// Description: LIN Description file created using Vector's DaVinci Network Designer

// Created: 22 Aug 2023 09:49:13

// Author: t035621

// Version: 0.0

// COM_MATRIX_T2_1.33.0

LIN_description_file;
LIN_protocol_version = "2.1";
LIN_language_version = "2.1";
LIN_speed = 9.6 kbps;

Nodes {
  Master: CCM, 5 ms, 0.5 ms ; // Climate Control Module
  Slaves: CabHeater, CCP, CFAN_L, CFAN_R, CFPM, CTS, DEFS, EACC_24V, WaterHeater ;
}

Signals {
  AtmospherePressureStatus: 8, 255, CCM, WaterHeater, CabHeater ;
  BacklightCmd: 5, 0, CCM, CCP ;
  CabTemperature_Status: 13, 8191, CCM, CabHeater ;
  CTS_Downtime: 12, 4095, CCM, CTS ;
  CTS_DrvDoorOpen: 1, 0, CCM, CTS ;
  CTS_DrvWindowStat: 4, 15, CCM, CTS ;
  CTS_GlazingType: 3, 7, CCM, CTS ;
  CTS_IradianceDrvSide: 6, 63, CCM, CTS ;
  CTS_IradiancePassSide: 6, 63, CCM, CTS ;
  CTS_ParameterSetting: 3, 7, CCM, CTS ;
  CTS_PassDoorOpen: 1, 0, CCM, CTS ;
  CTS_PassWindowStat: 4, 15, CCM, CTS ;
  CTS_RearDrvDoorOpen: 1, 0, CCM, CTS ;
  CTS_RearDrvWindowStat: 4, 15, CCM, CTS ;
  CTS_RearPassDoorOpen: 1, 0, CCM, CTS ;
  CTS_RearPassWindowStat: 4, 15, CCM, CTS ;
  CTS_SoftTopPos: 1, 0, CCM, CTS ;
  CTS_SunBlindPos: 1, 0, CCM, CTS ;
  CTS_SunBlindStat: 4, 15, CCM, CTS ;
  CTS_SunroofPos: 1, 0, CCM, CTS ;
  CTS_SunroofStat: 4, 15, CCM, CTS ;
  DiagInfoCabHeater: 7, 0, CabHeater, CCM ;
  DiagInfoCCP: 7, 0, CCP, CCM ;
  DiagInfoCFanL: 7, 0, CFAN_L, CCM ;
  DiagInfoCFanR: 7, 0, CFAN_R, CCM ;
  DiagInfoCFPM: 7, 0, CFPM, CCM ;
  DiagInfoDEFS: 7, 0, DEFS, CCM ;
  DiagInfoEACC: 7, 0, EACC_24V, CCM ;
  DiagInfoWaterHeater: 7, 0, WaterHeater, CCM ;
  ElecAcCompDrive_cmd: 2, 3, CCM, EACC_24V ;
  ElecAcCompTargetSpeed_cmd: 8, 255, CCM, EACC_24V ;
  ElecCondenserFanActivation_cmd: 2, 3, CCM, CFPM ;
  ElecCondFanOutputTarget_cmd: 8, 255, CCM, CFPM ;
  FanDirectionCFanLCmd: 2, 3, CCM, CFAN_L ;
  FanDirectionCFanRCmd: 2, 3, CCM, CFAN_R ;
  FanSpeedCFanLCmd: 7, 127, CCM, CFAN_L ;
  FanSpeedCFanRCmd: 7, 127, CCM, CFAN_R ;
  FuncIndIlluminationLevel: 3, 1, CCM, CCP ;
  LIN_AC_ButtonStatus: 2, 3, CCP, CCM ;
  LIN_AC_HVACFanIndication_cmd: 4, 15, CCM, CCP ;
  LIN_ACmode_IndicationCmd: 1, 0, CCM, CCP ;
  LIN_AHMaint_stat_BurnerLfTm: 8, 255, CabHeater, CCM ; // 254 Error ; 255 Not Available
  LIN_AHMaint_stat_FanLfTime: 8, 255, CabHeater, CCM ; // 254 Error ; 255 Not Available
  LIN_AHMaint_stat_FuelPmpLfTm: 8, 255, CabHeater, CCM ; // 254 Error ; 255 Not Available
  LIN_AHMaint_stat_GlowPlgLfTm: 8, 255, CabHeater, CCM ; // 254 Error ; 255 Not Available
  LIN_AHMaint_stat_WtrPmpLfTm: 8, 255, CabHeater, CCM ; // 254 Error ; 255 Not Available
  LIN_AHRunTest_Stat1_BurnerTest: 2, 3, CabHeater, CCM ;
  LIN_AHRunTest_Stat1_CO2Level: 8, 255, CabHeater, CCM ; // 254 Error ; 255 Not Available
  LIN_AHRunTest_Stat1_FuelFeeding: 2, 3, CabHeater, CCM ;
  LIN_AHRunTest_Stat1_OpVoltage: 8, 255, CabHeater, CCM ; // 254 Error ; 255 Not Available
  LIN_AHRunTest_Stat1_SetPointTmp: 5, 31, CabHeater, CCM ;
  LIN_AHRunTest_Stat1_TempOutlet: 8, 255, CabHeater, CCM ; // 254 Error ; 255 Not Available
  LIN_AHRunTest_Stat1_WaterSetTmp: 7, 127, CabHeater, CCM ; // 126 Error ; 127 Not available
  LIN_AHRunTest_Stat2_CabTemp: 13, 8191, CabHeater, CCM ; // 8190 Error; 8191 Not Available
  LIN_AHRunTest_Stat2_TempInlet: 10, 1023, CabHeater, CCM ; // 1022 Error ; 1023 Not available
  LIN_AHRunTest_Stat2_WaterTemp: 11, 2047, CabHeater, CCM ; // 2046 Error ; 2047 Not available
  LIN_AirBlowerSpeed_FreeWheelSt: 4, 15, CCP, CCM ;
  LIN_AirFloor_IndicationCmd: 1, 0, CCM, CCP ;
  LIN_AirFlowSelectionDownBtn_st: 2, 3, CCP, CCM ;
  LIN_AirFlowSelectionFrontBtn_s: 2, 3, CCP, CCM ;
  LIN_AirFlowSelectionUpBtn_stat: 2, 3, CCP, CCM ;
  LIN_AirHeater_Stat: 4, 15, CabHeater, CCM ;
  LIN_AirHeaterPowerStatus: 7, 127, CabHeater, CCM ;
  LIN_AirVent_IndicationCmd: 1, 0, CCM, CCP ;
  LIN_AirWindscreen_IndicationCm: 1, 0, CCM, CCP ;
  LIN_Area_9level_Indication_cmd: 4, 15, CCM, CCP ;
  LIN_Auto_ButtonStatus: 2, 3, CCP, CCM ;
  LIN_AutoMode_IndicationCmd: 1, 0, CCM, CCP ;
  LIN_CabInteriorTempVentilatedS: 10, 1023, CCP, CCM ; // 1022 Error; 1023 Not Available
  LIN_CFPM_stat: 2, 3, CFPM, CCM ;
  LIN_CFPMinputCurrent_stat: 8, 255, CFPM, CCM ;
  LIN_CFPMinputVoltage_stat: 9, 511, CFPM, CCM ;
  LIN_ClimateCtrlPanelSleep_cmd: 3, 7, CCM, CCP ;
  LIN_CTS_ItosRaw: 10, 1023, CTS, CCM ;
  LIN_CTS_RefRaw: 10, 1023, CTS, CCM ;
  LIN_CTS_ResponseError: 1, 0, CTS, CCM ;
  LIN_CTS_Solarradiance: 5, 30, CTS, CCM ;
  LIN_CTS_Status: 2, 3, CTS, CCM ;
  LIN_CTS_SunRaw: 10, 1023, CTS, CCM ;
  LIN_CTS_Temperature: 12, 4094, CTS, CCM ;
  LIN_CTS_TempOutofRange: 2, 3, CTS, CCM ;
  LIN_Eco_ButtonStatus: 2, 3, CCP, CCM ;
  LIN_ECOmode_IndicationCmd: 1, 0, CCM, CCP ;
  LIN_ElCondFanOutput_stat: 7, 127, CFPM, CCM ;
  LIN_ElCondFanOutputCurrent_sta: 8, 255, CFPM, CCM ;
  LIN_ElCondFanOutputVolt_stat: 9, 511, CFPM, CCM ;
  LIN_ElecAcCompInputCurrent_sta: 8, 255, EACC_24V, CCM ;
  LIN_ElecAcCompInVoltage_stat: 8, 255, EACC_24V, CCM ;
  LIN_ElecAcCompOperation_stat: 2, 3, EACC_24V, CCM ;
  LIN_ElecAcCompSleepMode_stat: 8, 255, EACC_24V, CCM ;
  LIN_ElecAcCompSpeed_stat: 8, 255, EACC_24V, CCM ;
  LIN_ElecAcCompTemp_stat: 8, 255, EACC_24V, CCM ;
  LIN_ElecAcCompWaitMode_stat: 8, 255, EACC_24V, CCM ;
  LIN_FanCurrentCFanLStat: 8, 255, CFAN_L, CCM ;
  LIN_FanCurrentCFanRStat: 8, 255, CFAN_R, CCM ;
  LIN_FanSpeedCFanLStat: 13, 8191, CFAN_L, CCM ;
  LIN_FanSpeedCFanRStat: 13, 8191, CFAN_R, CCM ;
  LIN_FanVoltageCFanLStat: 9, 511, CFAN_L, CCM ;
  LIN_FanVoltageCFanRStat: 9, 511, CFAN_R, CCM ;
  LIN_FogSensor_CabAirRH: 9, 511, DEFS, CCM ; // 510 Error ; 511 Not available
  LIN_FogSensor_CabAirTemp: 10, 1023, DEFS, CCM ; // 1022 Error ; 1023 Not available
  LIN_FogSensorWindscreenTemp_st: 11, 2047, DEFS, CCM ; // 2046 Error ; 2047 Not available
  LIN_Memo_ButtonStatus: 2, 3, CCP, CCM ;
  LIN_Memo_IndicationCmd: 1, 0, CCM, CCP ;
  LIN_ParkHeaterCooler_ButtonSta: 2, 3, CCP, CCM ;
  LIN_ParkingClimate_IndCmd: 3, 7, CCM, CCP ;
  LIN_Recirc_ButtonStatus: 2, 3, CCP, CCM ;
  LIN_Recirc_IndicationCmd: 1, 0, CCM, CCP ;
  LIN_Temperature_FreeWheelStatu: 4, 15, CCP, CCM ;
  LIN_TemperatureDec_ButtonStatu: 2, 3, CCP, CCM ;
  LIN_TemperatureInc_ButtonStatu: 2, 3, CCP, CCM ;
  LIN_TemperatureRqstIndicatio_c: 5, 31, CCM, CCP ;
  LIN_WaterHeater_Stat: 4, 15, WaterHeater, CCM ;
  LIN_WaterHeaterPowerStatus: 8, 255, WaterHeater, CCM ;
  LIN_WaterHeaterTemperature_Sta: 11, 2047, WaterHeater, CCM ; // 2046 Error ; 2047 Not available
  LIN_WaterPumpStatus: 2, 3, WaterHeater, CCM ;
  LIN_WHMaint_stat_BurnerLfTm: 8, 255, WaterHeater, CCM ; // 254 Error ; 255 Not Available
  LIN_WHMaint_stat_FanLfTime: 8, 255, WaterHeater, CCM ; // 254 Error ; 255 Not Available
  LIN_WHMaint_stat_FuelPmpLfTm: 8, 255, WaterHeater, CCM ; // 254 Error ; 255 Not Available
  LIN_WHMaint_stat_GlowPlgLfTm: 8, 255, WaterHeater, CCM ; // 254 Error ; 255 Not Available
  LIN_WHMaint_stat_WtrPmpLfTm: 8, 255, WaterHeater, CCM ; // 254 Error ; 255 Not Available
  LIN_WHRunTest_Stat1_BurnerTest: 2, 3, WaterHeater, CCM ;
  LIN_WHRunTest_Stat1_CO2Level: 8, 255, WaterHeater, CCM ; // 254 Error ; 255 Not Available
  LIN_WHRunTest_Stat1_FuelFeeding: 2, 3, WaterHeater, CCM ;
  LIN_WHRunTest_Stat1_OpVoltage: 8, 255, WaterHeater, CCM ; // 254 Error ; 255 Not Available
  LIN_WHRunTest_Stat1_SetPointTmp: 5, 31, WaterHeater, CCM ;
  LIN_WHRunTest_Stat1_TempOutlet: 8, 255, WaterHeater, CCM ; // 254 Error ; 255 Not Available
  LIN_WHRunTest_Stat1_WaterSetTmp: 7, 127, WaterHeater, CCM ; // 126 Error ; 127 Not available
  LIN_WHRunTest_Stat2_CabTemp: 13, 8191, WaterHeater, CCM ; // 8190 Error; 8191 Not Available
  LIN_WHRunTest_Stat2_TempInlet: 10, 1023, WaterHeater, CCM ; // 1022 Error ; 1023 Not available
  LIN_WHRunTest_Stat2_WaterTemp: 11, 2047, WaterHeater, CCM ; // 2046 Error ; 2047 Not available
  LIN_WindscreenDefrost_ButtonSt: 2, 3, CCP, CCM ;
  LIN_WindscreenDefrostInd_cmd: 1, 0, CCM, CCP ;
  PH_Activation_cmd: 3, 7, CCM, CabHeater, WaterHeater ;
  PHMasterMode_cmd_DosingPump: 7, 127, CCM, WaterHeater, CabHeater ; // 126 Error ; 127 Not available
  PHMasterMode_cmd_GlowPlug: 7, 127, CCM, CabHeater, WaterHeater ; // 126 Error ; 127 Not available
  PHMasterMode_cmd_HeatingFan: 7, 127, CCM, CabHeater, WaterHeater ; // 126 Error ; 127 Not available
  PHMasterMode_cmd_RunningTime: 8, 0, CCM, CabHeater, WaterHeater ;
  PHMasterMode_cmd_WaterPump: 2, 3, CCM, WaterHeater, CabHeater ;
  PHRunTest_cmd_Burner_cmd: 2, 3, CCM, WaterHeater, CabHeater ;
  PHRunTest_cmd_CO2Adjustment_cmd: 2, 3, CCM, CabHeater, WaterHeater ;
  PHRunTest_cmd_CO2Level: 8, 255, CCM, WaterHeater, CabHeater ; // 254 Error ; 255 Not Available
  PHRunTest_cmd_FuelFeeding_cmd: 2, 3, CCM, WaterHeater, CabHeater ;
  PHRunTest_cmd_FuelFeedTime: 9, 511, CCM, CabHeater, WaterHeater ; // 510 Error ; 511 Not Available
  PHRunTest_cmd_ReadSensor: 4, 15, CCM, WaterHeater, CabHeater ;
  PHRunTest_cmd_ResetCounter: 4, 15, CCM, CabHeater, WaterHeater ;
  PHRunTest_cmd_RstFaultCodes: 2, 3, CCM, CabHeater, WaterHeater ;
  ResponseErrorCabHeater: 1, 0, CabHeater, CCM ;
  ResponseErrorCCP: 1, 0, CCP, CCM ;
  ResponseErrorCFAN_L: 1, 0, CFAN_L, CCM ;
  ResponseErrorCFAN_R: 1, 0, CFAN_R, CCM ;
  ResponseErrorCFPM: 1, 0, CFPM, CCM ;
  ResponseErrorDEFS: 1, 0, DEFS, CCM ;
  ResponseErrorEACC: 1, 0, EACC_24V, CCM ;
  ResponseErrorWaterHeater: 1, 0, WaterHeater, CCM ;
  TempRqst_cmd: 5, 31, CCM, CabHeater ;
  WaterHeaterSetTemp_cmd: 7, 127, CCM, WaterHeater ;
}

Frames {
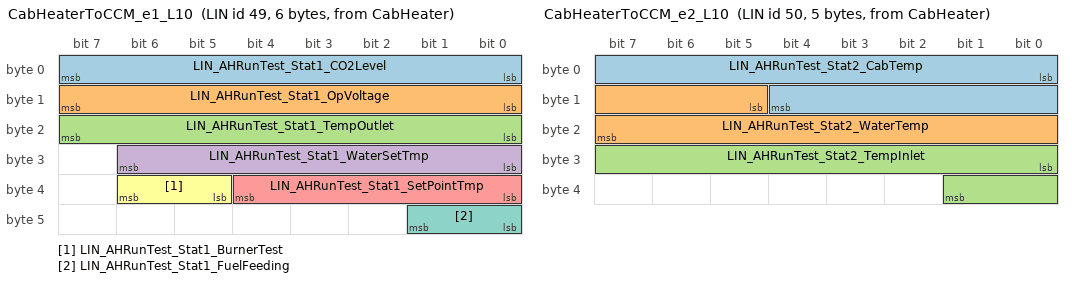
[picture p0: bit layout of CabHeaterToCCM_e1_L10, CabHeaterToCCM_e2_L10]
  CabHeaterToCCM_e1_L10: 49, CabHeater, 6 {
    LIN_AHRunTest_Stat1_CO2Level, 0 ;
    LIN_AHRunTest_Stat1_OpVoltage, 8 ;
    LIN_AHRunTest_Stat1_TempOutlet, 16 ;
    LIN_AHRunTest_Stat1_WaterSetTmp, 24 ;
    LIN_AHRunTest_Stat1_SetPointTmp, 32 ;
    LIN_AHRunTest_Stat1_BurnerTest, 37 ;
    LIN_AHRunTest_Stat1_FuelFeeding, 40 ;
  }
  CabHeaterToCCM_e2_L10: 50, CabHeater, 5 {
    LIN_AHRunTest_Stat2_CabTemp, 0 ;
    LIN_AHRunTest_Stat2_WaterTemp, 13 ;
    LIN_AHRunTest_Stat2_TempInlet, 24 ;
  }
  CabHeaterToCCM_FR2_L10: 46, CabHeater, 2 {
    LIN_AirHeaterPowerStatus, 0 ;
  }
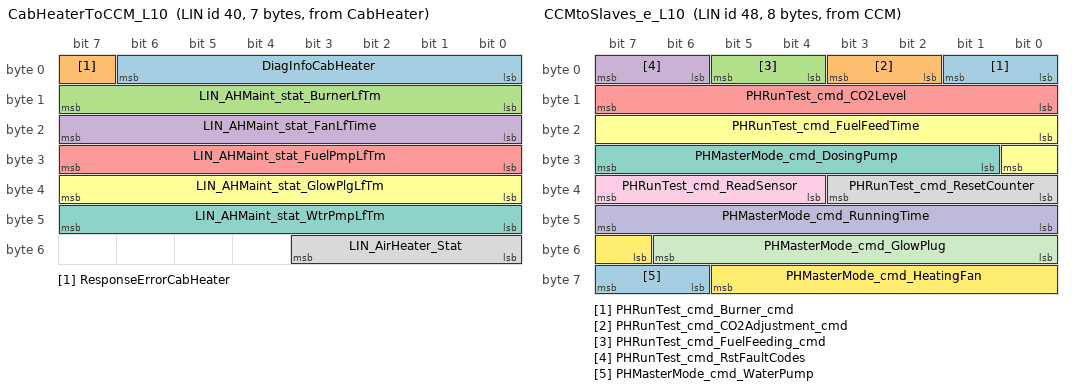
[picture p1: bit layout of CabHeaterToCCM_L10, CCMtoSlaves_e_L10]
  CabHeaterToCCM_L10: 40, CabHeater, 7 {
    DiagInfoCabHeater, 0 ;
    ResponseErrorCabHeater, 7 ;
    LIN_AHMaint_stat_BurnerLfTm, 8 ;
    LIN_AHMaint_stat_FanLfTime, 16 ;
    LIN_AHMaint_stat_FuelPmpLfTm, 24 ;
    LIN_AHMaint_stat_GlowPlgLfTm, 32 ;
    LIN_AHMaint_stat_WtrPmpLfTm, 40 ;
    LIN_AirHeater_Stat, 48 ;
  }
  CCMtoCTS_L10: 54, CCM, 8 {
    CTS_IradianceDrvSide, 0 ;
    CTS_DrvDoorOpen, 6 ;
    CTS_PassDoorOpen, 7 ;
    CTS_IradiancePassSide, 8 ;
    CTS_RearDrvDoorOpen, 14 ;
    CTS_RearPassDoorOpen, 15 ;
    CTS_DrvWindowStat, 16 ;
    CTS_PassWindowStat, 20 ;
    CTS_RearDrvWindowStat, 24 ;
    CTS_RearPassWindowStat, 28 ;
    CTS_SunroofStat, 32 ;
    CTS_SunBlindStat, 36 ;
    CTS_GlazingType, 40 ;
    CTS_ParameterSetting, 43 ;
    CTS_SunroofPos, 46 ;
    CTS_SunBlindPos, 47 ;
    CTS_Downtime, 48 ;
    CTS_SoftTopPos, 60 ;
  }
  CCMtoSlaves_e_L10: 48, CCM, 8 {
    PHRunTest_cmd_Burner_cmd, 0 ;
    PHRunTest_cmd_CO2Adjustment_cmd, 2 ;
    PHRunTest_cmd_FuelFeeding_cmd, 4 ;
    PHRunTest_cmd_RstFaultCodes, 6 ;
    PHRunTest_cmd_CO2Level, 8 ;
    PHRunTest_cmd_FuelFeedTime, 16 ;
    PHMasterMode_cmd_DosingPump, 25 ;
    PHRunTest_cmd_ResetCounter, 32 ;
    PHRunTest_cmd_ReadSensor, 36 ;
    PHMasterMode_cmd_RunningTime, 40 ;
    PHMasterMode_cmd_GlowPlug, 48 ;
    PHMasterMode_cmd_HeatingFan, 55 ;
    PHMasterMode_cmd_WaterPump, 62 ;
  }
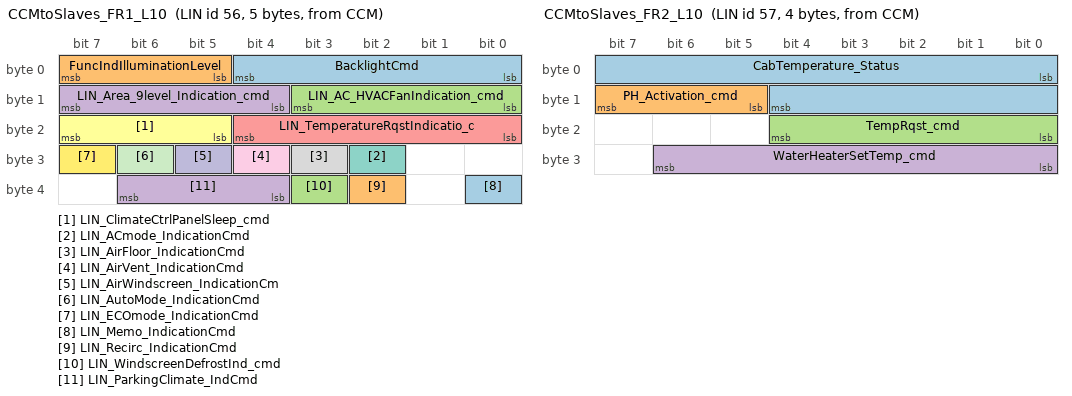
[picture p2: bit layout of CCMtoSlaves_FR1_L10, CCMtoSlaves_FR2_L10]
  CCMtoSlaves_FR1_L10: 56, CCM, 5 {
    BacklightCmd, 0 ;
    FuncIndIlluminationLevel, 5 ;
    LIN_AC_HVACFanIndication_cmd, 8 ;
    LIN_Area_9level_Indication_cmd, 12 ;
    LIN_TemperatureRqstIndicatio_c, 16 ;
    LIN_ClimateCtrlPanelSleep_cmd, 21 ;
    LIN_ACmode_IndicationCmd, 26 ;
    LIN_AirFloor_IndicationCmd, 27 ;
    LIN_AirVent_IndicationCmd, 28 ;
    LIN_AirWindscreen_IndicationCm, 29 ;
    LIN_AutoMode_IndicationCmd, 30 ;
    LIN_ECOmode_IndicationCmd, 31 ;
    LIN_Memo_IndicationCmd, 32 ;
    LIN_Recirc_IndicationCmd, 34 ;
    LIN_WindscreenDefrostInd_cmd, 35 ;
    LIN_ParkingClimate_IndCmd, 36 ;
  }
  CCMtoSlaves_FR2_L10: 57, CCM, 4 {
    CabTemperature_Status, 0 ;
    PH_Activation_cmd, 13 ;
    TempRqst_cmd, 16 ;
    WaterHeaterSetTemp_cmd, 24 ;
  }
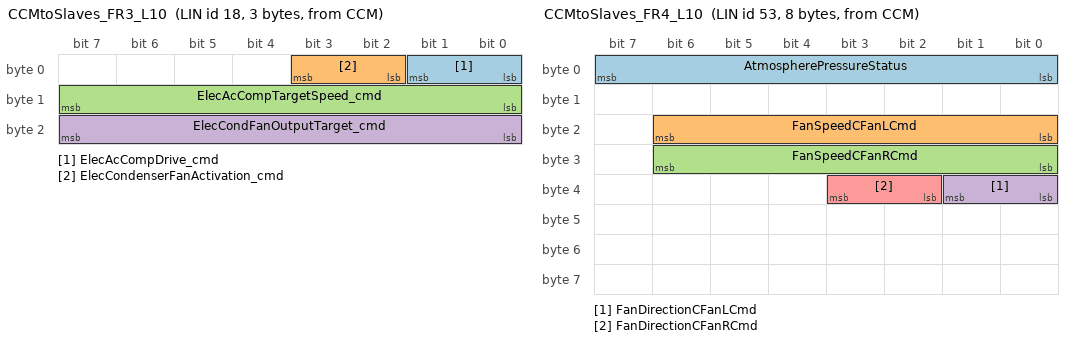
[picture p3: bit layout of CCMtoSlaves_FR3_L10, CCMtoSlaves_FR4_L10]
  CCMtoSlaves_FR3_L10: 18, CCM, 3 {
    ElecAcCompDrive_cmd, 0 ;
    ElecCondenserFanActivation_cmd, 2 ;
    ElecAcCompTargetSpeed_cmd, 8 ;
    ElecCondFanOutputTarget_cmd, 16 ;
  }
  CCMtoSlaves_FR4_L10: 53, CCM, 8 {
    AtmospherePressureStatus, 0 ;
    FanSpeedCFanLCmd, 16 ;
    FanSpeedCFanRCmd, 24 ;
    FanDirectionCFanLCmd, 32 ;
    FanDirectionCFanRCmd, 34 ;
  }
  CCPtoCCM_L10: 26, CCP, 7 {
    DiagInfoCCP, 0 ;
    ResponseErrorCCP, 7 ;
    LIN_AC_ButtonStatus, 8 ;
    LIN_AirBlowerSpeed_FreeWheelSt, 10 ;
    LIN_AirFlowSelectionDownBtn_st, 14 ;
    LIN_AirFlowSelectionFrontBtn_s, 16 ;
    LIN_AirFlowSelectionUpBtn_stat, 18 ;
    LIN_Auto_ButtonStatus, 20 ;
    LIN_Eco_ButtonStatus, 22 ;
    LIN_Memo_ButtonStatus, 24 ;
    LIN_ParkHeaterCooler_ButtonSta, 26 ;
    LIN_Recirc_ButtonStatus, 28 ;
    LIN_TemperatureDec_ButtonStatu, 30 ;
    LIN_Temperature_FreeWheelStatu, 32 ;
    LIN_TemperatureInc_ButtonStatu, 36 ;
    LIN_WindscreenDefrost_ButtonSt, 38 ;
    LIN_CabInteriorTempVentilatedS, 40 ;
  }
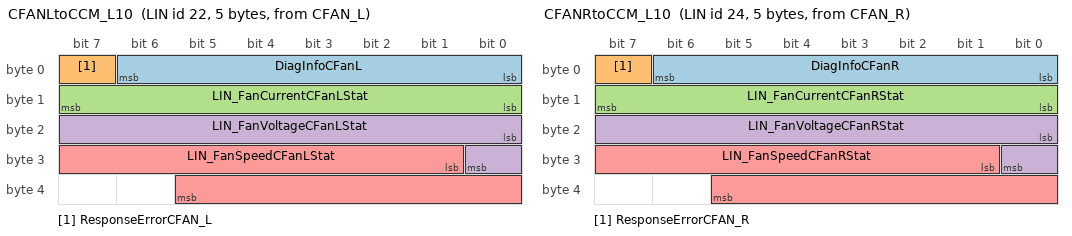
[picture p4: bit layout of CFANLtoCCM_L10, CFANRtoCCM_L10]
  CFANLtoCCM_L10: 22, CFAN_L, 5 {
    DiagInfoCFanL, 0 ;
    ResponseErrorCFAN_L, 7 ;
    LIN_FanCurrentCFanLStat, 8 ;
    LIN_FanVoltageCFanLStat, 16 ;
    LIN_FanSpeedCFanLStat, 25 ;
  }
  CFANRtoCCM_L10: 24, CFAN_R, 5 {
    DiagInfoCFanR, 0 ;
    ResponseErrorCFAN_R, 7 ;
    LIN_FanCurrentCFanRStat, 8 ;
    LIN_FanVoltageCFanRStat, 16 ;
    LIN_FanSpeedCFanRStat, 25 ;
  }
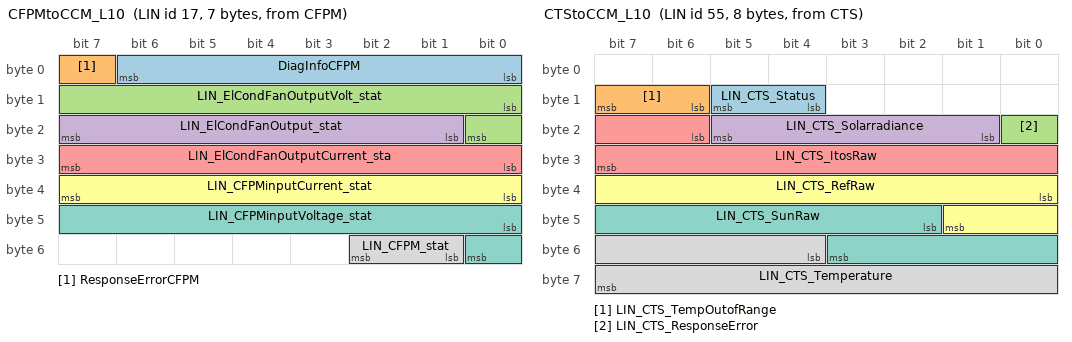
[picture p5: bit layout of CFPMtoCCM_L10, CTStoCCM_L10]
  CFPMtoCCM_L10: 17, CFPM, 7 {
    DiagInfoCFPM, 0 ;
    ResponseErrorCFPM, 7 ;
    LIN_ElCondFanOutputVolt_stat, 8 ;
    LIN_ElCondFanOutput_stat, 17 ;
    LIN_ElCondFanOutputCurrent_sta, 24 ;
    LIN_CFPMinputCurrent_stat, 32 ;
    LIN_CFPMinputVoltage_stat, 40 ;
    LIN_CFPM_stat, 49 ;
  }
  CTStoCCM_L10: 55, CTS, 8 {
    LIN_CTS_Status, 12 ;
    LIN_CTS_TempOutofRange, 14 ;
    LIN_CTS_ResponseError, 16 ;
    LIN_CTS_Solarradiance, 17 ;
    LIN_CTS_ItosRaw, 22 ;
    LIN_CTS_RefRaw, 32 ;
    LIN_CTS_SunRaw, 42 ;
    LIN_CTS_Temperature, 52 ;
  }
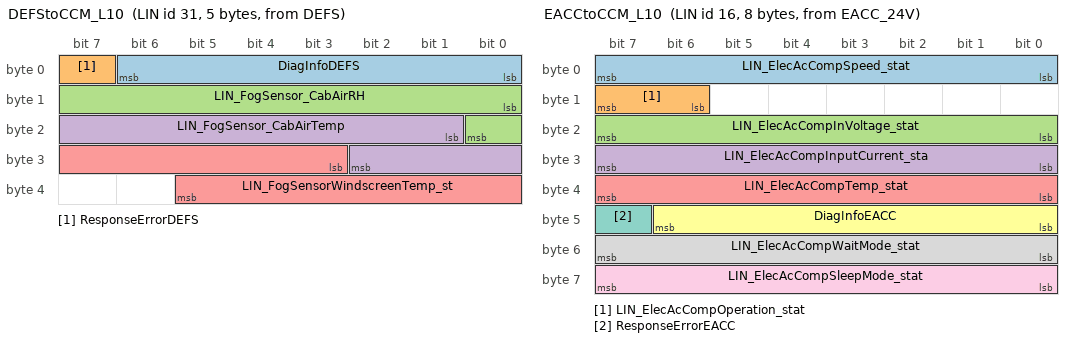
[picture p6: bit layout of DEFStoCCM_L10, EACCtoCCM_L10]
  DEFStoCCM_L10: 31, DEFS, 5 {
    DiagInfoDEFS, 0 ;
    ResponseErrorDEFS, 7 ;
    LIN_FogSensor_CabAirRH, 8 ;
    LIN_FogSensor_CabAirTemp, 17 ;
    LIN_FogSensorWindscreenTemp_st, 27 ;
  }
  EACCtoCCM_L10: 16, EACC_24V, 8 {
    LIN_ElecAcCompSpeed_stat, 0 ;
    LIN_ElecAcCompOperation_stat, 14 ;
    LIN_ElecAcCompInVoltage_stat, 16 ;
    LIN_ElecAcCompInputCurrent_sta, 24 ;
    LIN_ElecAcCompTemp_stat, 32 ;
    DiagInfoEACC, 40 ;
    ResponseErrorEACC, 47 ;
    LIN_ElecAcCompWaitMode_stat, 48 ;
    LIN_ElecAcCompSleepMode_stat, 56 ;
  }
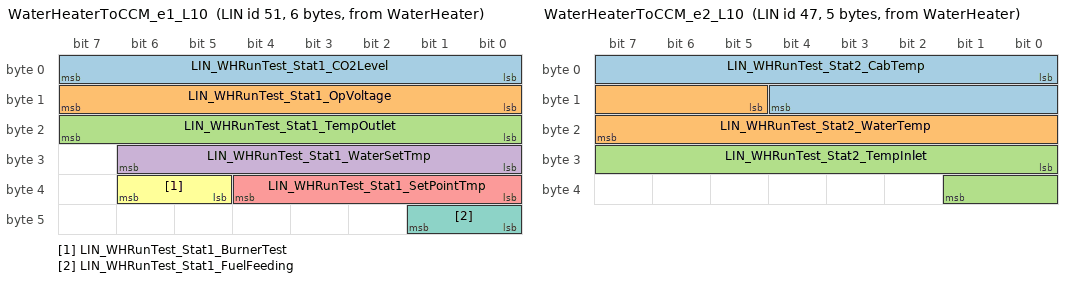
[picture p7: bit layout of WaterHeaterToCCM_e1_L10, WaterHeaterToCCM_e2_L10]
  WaterHeaterToCCM_e1_L10: 51, WaterHeater, 6 {
    LIN_WHRunTest_Stat1_CO2Level, 0 ;
    LIN_WHRunTest_Stat1_OpVoltage, 8 ;
    LIN_WHRunTest_Stat1_TempOutlet, 16 ;
    LIN_WHRunTest_Stat1_WaterSetTmp, 24 ;
    LIN_WHRunTest_Stat1_SetPointTmp, 32 ;
    LIN_WHRunTest_Stat1_BurnerTest, 37 ;
    LIN_WHRunTest_Stat1_FuelFeeding, 40 ;
  }
  WaterHeaterToCCM_e2_L10: 47, WaterHeater, 5 {
    LIN_WHRunTest_Stat2_CabTemp, 0 ;
    LIN_WHRunTest_Stat2_WaterTemp, 13 ;
    LIN_WHRunTest_Stat2_TempInlet, 24 ;
  }
  WaterHeaterToCCM_FR2_L10: 42, WaterHeater, 2 {
    LIN_WaterPumpStatus, 0 ;
    LIN_WaterHeaterPowerStatus, 8 ;
  }
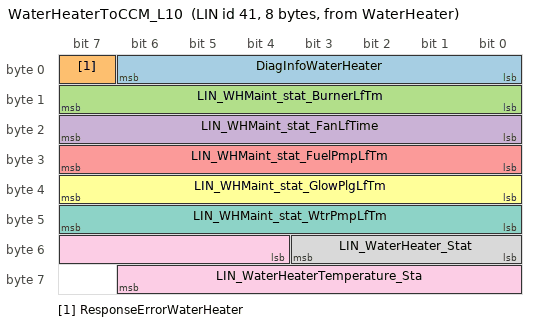
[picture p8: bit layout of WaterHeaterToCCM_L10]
  WaterHeaterToCCM_L10: 41, WaterHeater, 8 {
    DiagInfoWaterHeater, 0 ;
    ResponseErrorWaterHeater, 7 ;
    LIN_WHMaint_stat_BurnerLfTm, 8 ;
    LIN_WHMaint_stat_FanLfTime, 16 ;
    LIN_WHMaint_stat_FuelPmpLfTm, 24 ;
    LIN_WHMaint_stat_GlowPlgLfTm, 32 ;
    LIN_WHMaint_stat_WtrPmpLfTm, 40 ;
    LIN_WaterHeater_Stat, 48 ;
    LIN_WaterHeaterTemperature_Sta, 52 ;
  }
}

Node_attributes {
  CabHeater{
    LIN_protocol = "2.0" ;
    configured_NAD = 0x28 ;
    product_id = 0x5b, 0x0, 0 ;
    response_error = ResponseErrorCabHeater ;
    P2_min = 0 ms ;
    ST_min = 0 ms ;
    configurable_frames {
      CabHeaterToCCM_L10 = 0x28 ;
      CabHeaterToCCM_FR2_L10 = 0x2e ;
      CCMtoSlaves_e_L10 = 0x30 ;
      CabHeaterToCCM_e1_L10 = 0x31 ;
      CabHeaterToCCM_e2_L10 = 0x32 ;
      CCMtoSlaves_FR4_L10 = 0x35 ;
      CCMtoSlaves_FR2_L10 = 0x39 ;
    }
  } // Parking Air Heater Cab
  CCP{
    LIN_protocol = "2.0" ;
    configured_NAD = 0x1a ;
    product_id = 0x5b, 0x0, 0 ;
    response_error = ResponseErrorCCP ;
    P2_min = 0 ms ;
    ST_min = 0 ms ;
    configurable_frames {
      CCPtoCCM_L10 = 0x1a ;
      CCMtoSlaves_FR1_L10 = 0x38 ;
    }
  } // Climate Control Panel
  CFAN_L{
    LIN_protocol = "2.1" ;
    configured_NAD = 0x4d ;
    initial_NAD = 0x4d ;
    product_id = 0x5b, 0x0, 0 ;
    response_error = ResponseErrorCFAN_L ;
    N_As_timeout = 1000 ms ;
    N_Cr_timeout = 1000 ms ;
    configurable_frames {
      CFANLtoCCM_L10 ;
      CCMtoSlaves_FR4_L10 ;
    }
  } // CondenserFan Left
  CFAN_R{
    LIN_protocol = "2.1" ;
    configured_NAD = 0x4e ;
    initial_NAD = 0x4e ;
    product_id = 0x5b, 0x0, 0 ;
    response_error = ResponseErrorCFAN_R ;
    N_As_timeout = 1000 ms ;
    N_Cr_timeout = 1000 ms ;
    configurable_frames {
      CFANRtoCCM_L10 ;
      CCMtoSlaves_FR4_L10 ;
    }
  } // CondenserFan Right
  CFPM{
    LIN_protocol = "2.0" ;
    configured_NAD = 0x2a ;
    product_id = 0x5b, 0x0, 0 ;
    response_error = ResponseErrorCFPM ;
    P2_min = 0 ms ;
    ST_min = 0 ms ;
    configurable_frames {
      CFPMtoCCM_L10 = 0x11 ;
      CCMtoSlaves_FR3_L10 = 0x12 ;
    }
  } // Condenser Fan Power Module
  CTS{
    LIN_protocol = "2.1" ;
    configured_NAD = 0x64 ;
    initial_NAD = 0x64 ;
    product_id = 0x0, 0x0, 0 ;
    response_error = LIN_CTS_ResponseError ;
    N_As_timeout = 1000 ms ;
    N_Cr_timeout = 1000 ms ;
    configurable_frames {
      CTStoCCM_L10 ;
      CCMtoCTS_L10 ;
    }
  }
  DEFS{
    LIN_protocol = "2.0" ;
    configured_NAD = 0x1f ;
    product_id = 0x5b, 0x0, 0 ;
    response_error = ResponseErrorDEFS ;
    P2_min = 0 ms ;
    ST_min = 0 ms ;
    configurable_frames {
      DEFStoCCM_L10 = 0x1f ;
    }
  } // Defog Sensor
  EACC_24V{
    LIN_protocol = "2.0" ;
    configured_NAD = 0x26 ;
    product_id = 0x5b, 0x0, 0 ;
    response_error = ResponseErrorEACC ;
    P2_min = 0 ms ;
    ST_min = 0 ms ;
    configurable_frames {
      EACCtoCCM_L10 = 0x10 ;
      CCMtoSlaves_FR3_L10 = 0x12 ;
    }
  } // Electrical A/C Compressor
  WaterHeater{
    LIN_protocol = "2.0" ;
    configured_NAD = 0x29 ;
    product_id = 0x5b, 0x0, 0 ;
    response_error = ResponseErrorWaterHeater ;
    P2_min = 0 ms ;
    ST_min = 0 ms ;
    configurable_frames {
      WaterHeaterToCCM_L10 = 0x29 ;
      WaterHeaterToCCM_FR2_L10 = 0x2a ;
      WaterHeaterToCCM_e2_L10 = 0x2f ;
      WaterHeaterToCCM_e1_L10 = 0x33 ;
      CCMtoSlaves_FR4_L10 = 0x35 ;
      CCMtoSlaves_FR2_L10 = 0x39 ;
      CCMtoSlaves_e_L10 = 0x3a ;
    }
  } // Parking Water Heater Engine and Cab
}

Schedule_tables {
 Table0 {
    CCMtoSlaves_FR1_L10 delay 15 ms ;
    CCPtoCCM_L10 delay 20 ms ;
    CCMtoSlaves_FR2_L10 delay 15 ms ;
    CCMtoSlaves_FR1_L10 delay 15 ms ;
    CCPtoCCM_L10 delay 20 ms ;
    CabHeaterToCCM_L10 delay 20 ms ;
    CCMtoSlaves_FR1_L10 delay 15 ms ;
    CCPtoCCM_L10 delay 20 ms ;
    WaterHeaterToCCM_L10 delay 20 ms ;
    CCMtoSlaves_FR1_L10 delay 15 ms ;
    CCPtoCCM_L10 delay 20 ms ;
    DEFStoCCM_L10 delay 15 ms ;
    CCMtoSlaves_FR1_L10 delay 15 ms ;
    CCPtoCCM_L10 delay 20 ms ;
    CCMtoSlaves_FR3_L10 delay 15 ms ;
    CCMtoSlaves_FR1_L10 delay 15 ms ;
    CCPtoCCM_L10 delay 20 ms ;
    EACCtoCCM_L10 delay 20 ms ;
    CCMtoSlaves_FR1_L10 delay 15 ms ;
    CCPtoCCM_L10 delay 20 ms ;
    CFPMtoCCM_L10 delay 20 ms ;
  }
 Table_e {
    CCMtoSlaves_e_L10 delay 20 ms ;
    CabHeaterToCCM_e1_L10 delay 20 ms ;
    CabHeaterToCCM_e2_L10 delay 15 ms ;
    WaterHeaterToCCM_e1_L10 delay 20 ms ;
    WaterHeaterToCCM_e2_L10 delay 15 ms ;
    CCMtoSlaves_FR1_L10 delay 15 ms ;
    CCMtoSlaves_FR2_L10 delay 15 ms ;
    CCPtoCCM_L10 delay 20 ms ;
    CabHeaterToCCM_L10 delay 20 ms ;
    DEFStoCCM_L10 delay 15 ms ;
    WaterHeaterToCCM_L10 delay 20 ms ;
    CCMtoSlaves_FR3_L10 delay 15 ms ;
    EACCtoCCM_L10 delay 20 ms ;
    CFPMtoCCM_L10 delay 20 ms ;
  }
 MasterReq_SlaveResp_Table0 {
    MasterReq delay 20 ms ;
    SlaveResp delay 20 ms ;
    CCMtoSlaves_FR1_L10 delay 15 ms ;
    CCPtoCCM_L10 delay 20 ms ;
    CCMtoSlaves_FR2_L10 delay 15 ms ;
    CabHeaterToCCM_L10 delay 20 ms ;
    WaterHeaterToCCM_L10 delay 20 ms ;
    DEFStoCCM_L10 delay 15 ms ;
    CCMtoSlaves_FR3_L10 delay 15 ms ;
    EACCtoCCM_L10 delay 20 ms ;
    CFPMtoCCM_L10 delay 20 ms ;
  }
 Table01 {
    CCMtoSlaves_FR1_L10 delay 15 ms ;
    CCPtoCCM_L10 delay 20 ms ;
    CCMtoSlaves_FR2_L10 delay 15 ms ;
    CCMtoSlaves_FR1_L10 delay 15 ms ;
    CCPtoCCM_L10 delay 20 ms ;
    WaterHeaterToCCM_L10 delay 20 ms ;
    CCMtoSlaves_FR1_L10 delay 15 ms ;
    CCPtoCCM_L10 delay 20 ms ;
    CTStoCCM_L10 delay 20 ms ;
    CCMtoSlaves_FR1_L10 delay 15 ms ;
    CCPtoCCM_L10 delay 20 ms ;
    CCMtoSlaves_FR3_L10 delay 15 ms ;
    CCMtoSlaves_FR1_L10 delay 15 ms ;
    CCPtoCCM_L10 delay 20 ms ;
    EACCtoCCM_L10 delay 20 ms ;
    CCMtoSlaves_FR1_L10 delay 15 ms ;
    CCPtoCCM_L10 delay 20 ms ;
    CFPMtoCCM_L10 delay 20 ms ;
    CCMtoSlaves_FR1_L10 delay 15 ms ;
    CCPtoCCM_L10 delay 20 ms ;
    CCMtoCTS_L10 delay 20 ms ;
    CCMtoSlaves_FR1_L10 delay 15 ms ;
    CCPtoCCM_L10 delay 20 ms ;
    WaterHeaterToCCM_FR2_L10 delay 10 ms ;
  }
 MasterReq_SlaveResp_Table01 {
    MasterReq delay 20 ms ;
    SlaveResp delay 20 ms ;
    CCMtoSlaves_FR1_L10 delay 15 ms ;
    CCPtoCCM_L10 delay 20 ms ;
    CCMtoSlaves_FR2_L10 delay 15 ms ;
    WaterHeaterToCCM_L10 delay 20 ms ;
    CCMtoSlaves_FR3_L10 delay 15 ms ;
    EACCtoCCM_L10 delay 20 ms ;
    CFPMtoCCM_L10 delay 20 ms ;
    CTStoCCM_L10 delay 20 ms ;
    CCMtoCTS_L10 delay 20 ms ;
    WaterHeaterToCCM_FR2_L10 delay 10 ms ;
  }
 Table02 {
    CCMtoSlaves_FR1_L10 delay 15 ms ;
    CCPtoCCM_L10 delay 20 ms ;
    CCMtoSlaves_FR2_L10 delay 15 ms ;
    CCMtoSlaves_FR1_L10 delay 15 ms ;
    CCPtoCCM_L10 delay 20 ms ;
    CabHeaterToCCM_L10 delay 20 ms ;
    CCMtoSlaves_FR1_L10 delay 15 ms ;
    CCPtoCCM_L10 delay 20 ms ;
    CTStoCCM_L10 delay 20 ms ;
    CCMtoSlaves_FR1_L10 delay 15 ms ;
    CCPtoCCM_L10 delay 20 ms ;
    CCMtoSlaves_FR3_L10 delay 15 ms ;
    CCMtoSlaves_FR1_L10 delay 15 ms ;
    CCPtoCCM_L10 delay 20 ms ;
    EACCtoCCM_L10 delay 20 ms ;
    CCMtoSlaves_FR1_L10 delay 15 ms ;
    CCPtoCCM_L10 delay 20 ms ;
    CFPMtoCCM_L10 delay 20 ms ;
    CCMtoSlaves_FR1_L10 delay 15 ms ;
    CCPtoCCM_L10 delay 20 ms ;
    CCMtoCTS_L10 delay 20 ms ;
  }
 MasterReq_SlaveResp_Table02 {
    MasterReq delay 20 ms ;
    SlaveResp delay 20 ms ;
    CCMtoSlaves_FR1_L10 delay 15 ms ;
    CCPtoCCM_L10 delay 20 ms ;
    CCMtoSlaves_FR2_L10 delay 15 ms ;
    CabHeaterToCCM_L10 delay 20 ms ;
    CCMtoSlaves_FR3_L10 delay 15 ms ;
    EACCtoCCM_L10 delay 20 ms ;
    CFPMtoCCM_L10 delay 20 ms ;
    CTStoCCM_L10 delay 20 ms ;
    CCMtoCTS_L10 delay 20 ms ;
  }
 Table3 {
    CCMtoSlaves_FR1_L10 delay 15 ms ;
    CCPtoCCM_L10 delay 20 ms ;
    CCMtoSlaves_FR2_L10 delay 15 ms ;
    CCMtoSlaves_FR1_L10 delay 15 ms ;
    CCPtoCCM_L10 delay 20 ms ;
    WaterHeaterToCCM_L10 delay 20 ms ;
    CCMtoSlaves_FR1_L10 delay 15 ms ;
    CCPtoCCM_L10 delay 20 ms ;
    CTStoCCM_L10 delay 20 ms ;
    CCMtoSlaves_FR1_L10 delay 15 ms ;
    CCPtoCCM_L10 delay 20 ms ;
    CCMtoSlaves_FR3_L10 delay 15 ms ;
    CCMtoSlaves_FR1_L10 delay 15 ms ;
    CCPtoCCM_L10 delay 20 ms ;
    EACCtoCCM_L10 delay 20 ms ;
    CCMtoSlaves_FR1_L10 delay 15 ms ;
    CCPtoCCM_L10 delay 20 ms ;
    CFANLtoCCM_L10 delay 15 ms ;
    CCMtoSlaves_FR1_L10 delay 15 ms ;
    CCPtoCCM_L10 delay 20 ms ;
    CCMtoCTS_L10 delay 20 ms ;
    CCMtoSlaves_FR1_L10 delay 15 ms ;
    CCPtoCCM_L10 delay 20 ms ;
    WaterHeaterToCCM_FR2_L10 delay 10 ms ;
    CCMtoSlaves_FR1_L10 delay 15 ms ;
    CCPtoCCM_L10 delay 20 ms ;
    CCMtoSlaves_FR4_L10 delay 20 ms ;
    CCMtoSlaves_FR1_L10 delay 15 ms ;
    CCPtoCCM_L10 delay 20 ms ;
    CFANRtoCCM_L10 delay 15 ms ;
  }
 MasterReq_SlaveResp_Table3 {
    MasterReq delay 20 ms ;
    SlaveResp delay 20 ms ;
    CCMtoSlaves_FR1_L10 delay 15 ms ;
    CCPtoCCM_L10 delay 20 ms ;
    CCMtoSlaves_FR2_L10 delay 15 ms ;
    WaterHeaterToCCM_L10 delay 20 ms ;
    CCMtoSlaves_FR3_L10 delay 15 ms ;
    EACCtoCCM_L10 delay 20 ms ;
    CTStoCCM_L10 delay 20 ms ;
    CCMtoCTS_L10 delay 20 ms ;
    WaterHeaterToCCM_FR2_L10 delay 10 ms ;
    CFANLtoCCM_L10 delay 15 ms ;
    CFANRtoCCM_L10 delay 15 ms ;
    CCMtoSlaves_FR4_L10 delay 20 ms ;
  }
 Table4 {
    CCMtoSlaves_FR1_L10 delay 15 ms ;
    CCPtoCCM_L10 delay 20 ms ;
    CCMtoSlaves_FR2_L10 delay 15 ms ;
    CCMtoSlaves_FR1_L10 delay 15 ms ;
    CCPtoCCM_L10 delay 20 ms ;
    CabHeaterToCCM_L10 delay 20 ms ;
    CCMtoSlaves_FR1_L10 delay 15 ms ;
    CCPtoCCM_L10 delay 20 ms ;
    CTStoCCM_L10 delay 20 ms ;
    CCMtoSlaves_FR1_L10 delay 15 ms ;
    CCPtoCCM_L10 delay 20 ms ;
    CCMtoSlaves_FR3_L10 delay 15 ms ;
    CCMtoSlaves_FR1_L10 delay 15 ms ;
    CCPtoCCM_L10 delay 20 ms ;
    EACCtoCCM_L10 delay 20 ms ;
    CCMtoSlaves_FR1_L10 delay 15 ms ;
    CCPtoCCM_L10 delay 20 ms ;
    CCMtoSlaves_FR4_L10 delay 20 ms ;
    CCMtoSlaves_FR1_L10 delay 15 ms ;
    CCPtoCCM_L10 delay 20 ms ;
    CCMtoCTS_L10 delay 20 ms ;
    CCMtoSlaves_FR1_L10 delay 15 ms ;
    CCPtoCCM_L10 delay 20 ms ;
    CabHeaterToCCM_FR2_L10 delay 10 ms ;
    CCMtoSlaves_FR1_L10 delay 15 ms ;
    CCPtoCCM_L10 delay 20 ms ;
    CFANLtoCCM_L10 delay 15 ms ;
    CCMtoSlaves_FR1_L10 delay 15 ms ;
    CCPtoCCM_L10 delay 20 ms ;
    CFANRtoCCM_L10 delay 15 ms ;
  }
 MasterReq_SlaveResp_Table4 {
    MasterReq delay 20 ms ;
    SlaveResp delay 20 ms ;
    CCMtoSlaves_FR1_L10 delay 15 ms ;
    CCPtoCCM_L10 delay 20 ms ;
    CCMtoSlaves_FR2_L10 delay 15 ms ;
    CabHeaterToCCM_L10 delay 20 ms ;
    DEFStoCCM_L10 delay 15 ms ;
    CCMtoSlaves_FR3_L10 delay 15 ms ;
    EACCtoCCM_L10 delay 20 ms ;
    CabHeaterToCCM_FR2_L10 delay 10 ms ;
    CTStoCCM_L10 delay 20 ms ;
    CCMtoCTS_L10 delay 20 ms ;
    CFANLtoCCM_L10 delay 15 ms ;
    CFANRtoCCM_L10 delay 15 ms ;
    CCMtoSlaves_FR4_L10 delay 20 ms ;
  }
 Table5 {
    CCMtoSlaves_FR2_L10 delay 15 ms ;
    CCMtoSlaves_FR4_L10 delay 20 ms ;
    CabHeaterToCCM_L10 delay 20 ms ;
    CabHeaterToCCM_FR2_L10 delay 10 ms ;
    WaterHeaterToCCM_FR2_L10 delay 10 ms ;
    WaterHeaterToCCM_L10 delay 20 ms ;
    CCMtoSlaves_FR3_L10 delay 15 ms ;
    EACCtoCCM_L10 delay 20 ms ;
    CFANLtoCCM_L10 delay 15 ms ;
    CFANRtoCCM_L10 delay 15 ms ;
    CCMtoCTS_L10 delay 20 ms ;
    CTStoCCM_L10 delay 20 ms ;
  }
 MasterReq_SlaveResp_Table5 {
    MasterReq delay 20 ms ;
    SlaveResp delay 20 ms ;
    CCMtoSlaves_FR2_L10 delay 15 ms ;
    CCMtoSlaves_FR4_L10 delay 20 ms ;
    CabHeaterToCCM_L10 delay 20 ms ;
    CabHeaterToCCM_FR2_L10 delay 10 ms ;
    WaterHeaterToCCM_FR2_L10 delay 10 ms ;
    WaterHeaterToCCM_L10 delay 20 ms ;
    CCMtoSlaves_FR3_L10 delay 15 ms ;
    EACCtoCCM_L10 delay 20 ms ;
    CFANLtoCCM_L10 delay 15 ms ;
    CFANRtoCCM_L10 delay 15 ms ;
    CCMtoCTS_L10 delay 20 ms ;
    CTStoCCM_L10 delay 20 ms ;
  }
 Table6 {
    CCMtoSlaves_FR1_L10 delay 15 ms ;
    CCPtoCCM_L10 delay 20 ms ;
    CCMtoSlaves_FR2_L10 delay 15 ms ;
    CCMtoSlaves_FR1_L10 delay 15 ms ;
    CCPtoCCM_L10 delay 20 ms ;
    WaterHeaterToCCM_L10 delay 20 ms ;
    CCMtoSlaves_FR1_L10 delay 15 ms ;
    CCPtoCCM_L10 delay 20 ms ;
    CCMtoSlaves_FR4_L10 delay 20 ms ;
    CCMtoSlaves_FR1_L10 delay 15 ms ;
    CCPtoCCM_L10 delay 20 ms ;
    CCMtoSlaves_FR3_L10 delay 15 ms ;
    CCMtoSlaves_FR1_L10 delay 15 ms ;
    CCPtoCCM_L10 delay 20 ms ;
    EACCtoCCM_L10 delay 20 ms ;
    CCMtoSlaves_FR1_L10 delay 15 ms ;
    CCPtoCCM_L10 delay 20 ms ;
    CFPMtoCCM_L10 delay 20 ms ;
    CCMtoSlaves_FR1_L10 delay 15 ms ;
    CCPtoCCM_L10 delay 20 ms ;
    WaterHeaterToCCM_FR2_L10 delay 10 ms ;
  }
 MasterReq_SlaveResp_Table6 {
    MasterReq delay 20 ms ;
    SlaveResp delay 20 ms ;
    CCMtoSlaves_FR1_L10 delay 15 ms ;
    CCPtoCCM_L10 delay 20 ms ;
    CCMtoSlaves_FR2_L10 delay 15 ms ;
    WaterHeaterToCCM_L10 delay 20 ms ;
    CCMtoSlaves_FR3_L10 delay 15 ms ;
    EACCtoCCM_L10 delay 20 ms ;
    CFPMtoCCM_L10 delay 20 ms ;
    CCMtoSlaves_FR4_L10 delay 20 ms ;
    WaterHeaterToCCM_FR2_L10 delay 10 ms ;
  }
 Table7 {
    CCMtoSlaves_FR1_L10 delay 15 ms ;
    CCPtoCCM_L10 delay 20 ms ;
    CCMtoSlaves_FR2_L10 delay 15 ms ;
    CCMtoSlaves_FR1_L10 delay 15 ms ;
    CCPtoCCM_L10 delay 20 ms ;
    CabHeaterToCCM_L10 delay 20 ms ;
    CCMtoSlaves_FR1_L10 delay 15 ms ;
    CCPtoCCM_L10 delay 20 ms ;
    CCMtoSlaves_FR4_L10 delay 20 ms ;
    CCMtoSlaves_FR1_L10 delay 15 ms ;
    CCPtoCCM_L10 delay 20 ms ;
    CCMtoSlaves_FR3_L10 delay 15 ms ;
    CCMtoSlaves_FR1_L10 delay 15 ms ;
    CCPtoCCM_L10 delay 20 ms ;
    EACCtoCCM_L10 delay 20 ms ;
    CCMtoSlaves_FR1_L10 delay 15 ms ;
    CCPtoCCM_L10 delay 20 ms ;
    CFPMtoCCM_L10 delay 20 ms ;
  }
 MasterReq_SlaveResp_Table7 {
    MasterReq delay 20 ms ;
    SlaveResp delay 20 ms ;
    CCMtoSlaves_FR1_L10 delay 15 ms ;
    CCPtoCCM_L10 delay 20 ms ;
    CCMtoSlaves_FR2_L10 delay 15 ms ;
    CabHeaterToCCM_L10 delay 20 ms ;
    CCMtoSlaves_FR4_L10 delay 20 ms ;
    CCMtoSlaves_FR3_L10 delay 15 ms ;
    EACCtoCCM_L10 delay 20 ms ;
    CFPMtoCCM_L10 delay 20 ms ;
  }
}

Signal_encoding_types {
  AtmospherePressureStatus {
    physical_value, 0, 255, 0.5, 0, "kPa" ;
  }
  BacklightCmd {
    logical_value, 0, "BacklightCmd_BacklightOff" ;
    logical_value, 1, "BacklightCmd_BacklightLevel1" ;
    logical_value, 2, "BacklightCmd_BacklightLevel2" ;
    logical_value, 3, "BacklightCmd_BacklightLevel3" ;
    logical_value, 4, "BacklightCmd_BacklightLevel4" ;
    logical_value, 5, "BacklightCmd_BacklightLevel5" ;
    logical_value, 6, "BacklightCmd_BacklightLevel6" ;
    logical_value, 7, "BacklightCmd_BacklightLevel7" ;
    logical_value, 8, "BacklightCmd_BacklightLevel8" ;
    logical_value, 9, "BacklightCmd_BacklightLevel9" ;
    logical_value, 10, "BacklightCmd_BacklightLevel10" ;
    logical_value, 11, "BacklightCmd_BacklightLevel11" ;
    logical_value, 12, "BacklightCmd_BacklightLevel12" ;
    logical_value, 13, "BacklightCmd_BacklightLevel13" ;
    logical_value, 14, "BacklightCmd_BacklightLevel14" ;
    logical_value, 15, "BacklightCmd_BacklightLevel15" ;
    logical_value, 16, "BacklightCmd_BacklightLevel16" ;
    logical_value, 30, "BacklightCmd_Error" ;
    logical_value, 31, "BacklightCmd_NotAvailable" ;
  }
  CabTemperature_Status {
    physical_value, 0, 8191, 0.025, -40, "DegreeC" ;
  }
  CTS_Downtime {
    physical_value, 0, 4095, 1, 0, "min" ;
  }
  CTS_DrvWindowStat {
    physical_value, 0, 15, 10, 0, "Percent" ;
  }
  CTS_GlazingType {
    logical_value, 0, "CTS_GlazingType_NormalGlazing" ;
    logical_value, 1, "CTS_GlazingType_HeatProtectedGlass" ;
    logical_value, 2, "CTS_GlazingType_Spare1" ;
    logical_value, 3, "CTS_GlazingType_Spare2" ;
    logical_value, 4, "CTS_GlazingType_Spare3" ;
    logical_value, 5, "CTS_GlazingType_Spare4" ;
    logical_value, 6, "CTS_GlazingType_Spare5" ;
    logical_value, 7, "CTS_GlazingType_Spare6" ;
  }
  CTS_IradianceDrvSide {
    physical_value, 0, 63, 20, 0, "W_per_m_squared" ;
  }
  CTS_IradiancePassSide {
    physical_value, 0, 63, 20, 0, "W_per_m_squared" ;
  }
  CTS_PassWindowStat {
    physical_value, 0, 15, 10, 0, "Percent" ;
  }
  CTS_RearDrvWindowStat {
    physical_value, 0, 15, 10, 0, "Percent" ;
  }
  CTS_RearPassWindowStat {
    physical_value, 0, 15, 10, 0, "Percent" ;
  }
  CTS_SunBlindStat {
    physical_value, 0, 15, 10, 0, "Percent" ;
  }
  CTS_SunroofStat {
    physical_value, 0, 15, 10, 0, "Percent" ;
  }
  DiagInfoCabHeater {
    physical_value, 0, 127, 1, 0, "NotApplicable" ;
  }
  DiagInfoCCP {
    physical_value, 0, 127, 1, 0, "NotApplicable" ;
  }
  DiagInfoCFanL {
    physical_value, 0, 127, 1, 0, "NotApplicable" ;
  }
  DiagInfoCFanR {
    physical_value, 0, 127, 1, 0, "NotApplicable" ;
  }
  DiagInfoCFPM {
    physical_value, 0, 127, 1, 0, "NotApplicable" ;
  }
  DiagInfoDEFS {
    physical_value, 0, 127, 1, 0, "NotApplicable" ;
  }
  DiagInfoEACC {
    physical_value, 0, 127, 1, 0, "NotApplicable" ;
  }
  DiagInfoWaterHeater {
    physical_value, 0, 127, 1, 0, "NotApplicable" ;
  }
  ElecAcCompDrive_cmd {
    logical_value, 0, "ElecAcCompDrive_cmd_NoActivationRequested" ;
    logical_value, 1, "ElecAcCompDrive_cmd_ActivationRequested" ;
    logical_value, 2, "ElecAcCompDrive_cmd_Error" ;
    logical_value, 3, "ElecAcCompDrive_cmd_NotAvailable" ;
  }
  ElecAcCompTargetSpeed_cmd {
    physical_value, 0, 255, 50, 0, "rpm" ;
  }
  ElecCondenserFanActivation_cmd {
    logical_value, 0, "Request_NotRequested" ;
    logical_value, 1, "Request_RequestActive" ;
    logical_value, 2, "Request_Error" ;
    logical_value, 3, "Request_NotAvailable" ;
  }
  ElecCondFanOutputTarget_cmd {
    physical_value, 0, 255, 0.1, 0, "V" ;
  }
  FanDirectionCFanLCmd {
    logical_value, 0, "FanDirCFanCmd_CW_RotorView" ;
    logical_value, 1, "FanDirCFanCmd_CCW_RotorView" ;
    logical_value, 2, "FanDirCFanCmd_Error" ;
    logical_value, 3, "FanDirCFanCmd_NotAvailable" ;
  }
  FanDirectionCFanRCmd {
    logical_value, 0, "FanDirCFanCmd_CW_RotorView" ;
    logical_value, 1, "FanDirCFanCmd_CCW_RotorView" ;
    logical_value, 2, "FanDirCFanCmd_Error" ;
    logical_value, 3, "FanDirCFanCmd_NotAvailable" ;
  }
  FanSpeedCFanLCmd {
    physical_value, 0, 127, 1, 0, "Percent" ;
  }
  FanSpeedCFanRCmd {
    physical_value, 0, 127, 1, 0, "Percent" ;
  }
  FuncIndIlluminationLevel {
    logical_value, 0, "FuncIndIlluminationLevel_IlluminationOff" ;
    logical_value, 1, "FuncIndIlluminationLevel_IlluminationLevel1" ;
    logical_value, 2, "FuncIndIlluminationLevel_IlluminationLevel2" ;
    logical_value, 3, "FuncIndIlluminationLevel_IlluminationLevel3" ;
    logical_value, 4, "FuncIndIlluminationLevel_IlluminationLevel4" ;
    logical_value, 5, "FuncIndIlluminationLevel_Spare" ;
    logical_value, 6, "FuncIndIlluminationLevel_Error" ;
    logical_value, 7, "FuncIndIlluminationLevel_NotAvailable" ;
  }
  LIN_AC_ButtonStatus {
    logical_value, 0, "PushButtonStatus_Neutral" ;
    logical_value, 1, "PushButtonStatus_Pushed" ;
    logical_value, 2, "PushButtonStatus_Error" ;
    logical_value, 3, "PushButtonStatus_NotAvailable" ;
  }
  LIN_AC_HVACFanIndication_cmd {
    logical_value, 0, "AC_HVACFanIndication_cmd_OFF" ;
    logical_value, 1, "AC_HVACFanIndication_cmd_SPEED1" ;
    logical_value, 2, "AC_HVACFanIndication_cmd_SPEED2" ;
    logical_value, 3, "AC_HVACFanIndication_cmd_SPEED3" ;
    logical_value, 4, "AC_HVACFanIndication_cmd_SPEED4" ;
    logical_value, 5, "AC_HVACFanIndication_cmd_SPEED5" ;
    logical_value, 6, "AC_HVACFanIndication_cmd_SPEED6" ;
    logical_value, 7, "AC_HVACFanIndication_cmd_SPEED7" ;
    logical_value, 8, "AC_HVACFanIndication_cmd_SPEED8" ;
    logical_value, 9, "AC_HVACFanIndication_cmd_SPEED9" ;
    logical_value, 10, "AC_HVACFanIndication_cmd_SPEED10" ;
    logical_value, 11, "AC_HVACFanIndication_cmd_Spare" ;
    logical_value, 12, "AC_HVACFanIndication_cmd_Spare_01" ;
    logical_value, 13, "AC_HVACFanIndication_cmd_Spare_02" ;
    logical_value, 14, "AC_HVACFanIndication_cmd_Error" ;
    logical_value, 15, "AC_HVACFanIndication_cmd_NotAvailable" ;
  }
  LIN_ACmode_IndicationCmd {
    logical_value, 0, "IndicationCmd_OFFLEDNotActivated" ;
    logical_value, 1, "IndicationCmd_ONLEDActivated" ;
  }
  LIN_AHMaint_stat_BurnerLfTm {
    physical_value, 0, 255, 20, 0, "h" ;
  } // 254 Error ; 255 Not Available
  LIN_AHMaint_stat_FanLfTime {
    physical_value, 0, 255, 20, 0, "h" ;
  } // 254 Error ; 255 Not Available
  LIN_AHMaint_stat_FuelPmpLfTm {
    physical_value, 0, 255, 20, 0, "h" ;
  } // 254 Error ; 255 Not Available
  LIN_AHMaint_stat_GlowPlgLfTm {
    physical_value, 0, 255, 20, 0, "h" ;
  } // 254 Error ; 255 Not Available
  LIN_AHMaint_stat_WtrPmpLfTm {
    physical_value, 0, 255, 20, 0, "h" ;
  } // 254 Error ; 255 Not Available
  LIN_AHRunTest_Stat1_BurnerTest {
    logical_value, 0, "BurnerTest_Status_BurnerTestSequenceValidated" ;
    logical_value, 1, "BurnerTest_Status_BurnerTestSequenceNotValidated" ;
    logical_value, 2, "BurnerTest_Status_Error" ;
    logical_value, 3, "BurnerTest_Status_NotAvailable" ;
  }
  LIN_AHRunTest_Stat1_CO2Level {
    physical_value, 0, 255, 0.08, -10, "Percent" ;
  } // 254 Error ; 255 Not Available
  LIN_AHRunTest_Stat1_FuelFeeding {
    logical_value, 0, "FuelFeeding_Status_FuelLineFeedingSequenceValidated" ;
    logical_value, 1, "FuelFeeding_Status_FuelLineFeedingSequenceNotValidated" ;
    logical_value, 2, "FuelFeeding_Status_Error" ;
    logical_value, 3, "FuelFeeding_Status_NotAvailable" ;
  }
  LIN_AHRunTest_Stat1_OpVoltage {
    physical_value, 0, 255, 0.14, 0, "V" ;
  } // 254 Error ; 255 Not Available
  LIN_AHRunTest_Stat1_SetPointTmp {
    logical_value, 0, "SetPointTemp_14_0DegC" ;
    logical_value, 1, "SetPointTemp_15_0DegC" ;
    logical_value, 2, "SetPointTemp_16_0DegC" ;
    logical_value, 3, "SetPointTemp_16_5DegC" ;
    logical_value, 4, "SetPointTemp_17_0DegC" ;
    logical_value, 5, "SetPointTemp_17_5DegC" ;
    logical_value, 6, "SetPointTemp_18_0DegC" ;
    logical_value, 7, "SetPointTemp_18_5DegC" ;
    logical_value, 8, "SetPointTemp_19_0DegC" ;
    logical_value, 9, "SetPointTemp_19_5DegC" ;
    logical_value, 10, "SetPointTemp_20_0DegC" ;
    logical_value, 11, "SetPointTemp_20_5DegC" ;
    logical_value, 12, "SetPointTemp_21_0DegC" ;
    logical_value, 13, "SetPointTemp_21_5DegC" ;
    logical_value, 14, "SetPointTemp_22_0DegC" ;
    logical_value, 15, "SetPointTemp_22_5DegC" ;
    logical_value, 16, "SetPointTemp_23_0DegC" ;
    logical_value, 17, "SetPointTemp_23_5DegC" ;
    logical_value, 18, "SetPointTemp_24_0DegC" ;
    logical_value, 19, "SetPointTemp_24_5DegC" ;
    logical_value, 20, "SetPointTemp_25_0DegC" ;
    logical_value, 21, "SetPointTemp_25_5DegC" ;
    logical_value, 22, "SetPointTemp_26_0DegC" ;
    logical_value, 23, "SetPointTemp_27_0DegC" ;
    logical_value, 24, "SetPointTemp_28_0DegC" ;
    logical_value, 25, "SetPointTemp_29_0DegC" ;
    logical_value, 26, "SetPointTemp_30_0DegC" ;
    logical_value, 27, "SetPointTemp_Spare" ;
    logical_value, 28, "SetPointTemp_Spare_01" ;
    logical_value, 29, "SetPointTemp_Spare_02" ;
    logical_value, 30, "SetPointTemp_Error" ;
    logical_value, 31, "SetPointTemp_NotAvailable" ;
  }
  LIN_AHRunTest_Stat1_TempOutlet {
    physical_value, 0, 255, 1, -50, "DegreeC" ;
  } // 254 Error ; 255 Not Available
  LIN_AHRunTest_Stat1_WaterSetTmp {
    physical_value, 0, 127, 1, 0, "DegreeC" ;
  } // 126 Error ; 127 Not available
  LIN_AHRunTest_Stat2_CabTemp {
    physical_value, 0, 8191, 0.025, -40, "DegreeC" ;
  } // 8190 Error; 8191 Not Available
  LIN_AHRunTest_Stat2_TempInlet {
    physical_value, 0, 1023, 0.125, -50, "DegreeC" ;
  } // 1022 Error ; 1023 Not available
  LIN_AHRunTest_Stat2_WaterTemp {
    physical_value, 0, 2047, 0.1, -40, "DegreeC" ;
  } // 2046 Error ; 2047 Not available
  LIN_AirBlowerSpeed_FreeWheelSt {
    logical_value, 0, "FreeWheel_Status_NoMovement" ;
    logical_value, 1, "FreeWheel_Status_1StepClockwise" ;
    logical_value, 2, "FreeWheel_Status_2StepsClockwise" ;
    logical_value, 3, "FreeWheel_Status_3StepsClockwise" ;
    logical_value, 4, "FreeWheel_Status_4StepsClockwise" ;
    logical_value, 5, "FreeWheel_Status_5StepsClockwise" ;
    logical_value, 6, "FreeWheel_Status_6StepsClockwise" ;
    logical_value, 7, "FreeWheel_Status_1StepCounterClockwise" ;
    logical_value, 8, "FreeWheel_Status_2StepsCounterClockwise" ;
    logical_value, 9, "FreeWheel_Status_3StepsCounterClockwise" ;
    logical_value, 10, "FreeWheel_Status_4StepsCounterClockwise" ;
    logical_value, 11, "FreeWheel_Status_5StepsCounterClockwise" ;
    logical_value, 12, "FreeWheel_Status_6StepsCounterClockwise" ;
    logical_value, 13, "FreeWheel_Status_Spare" ;
    logical_value, 14, "FreeWheel_Status_Error" ;
    logical_value, 15, "FreeWheel_Status_NotAvailable" ;
  }
  LIN_AirFloor_IndicationCmd {
    logical_value, 0, "IndicationCmd_OFFLEDNotActivated" ;
    logical_value, 1, "IndicationCmd_ONLEDActivated" ;
  }
  LIN_AirFlowSelectionDownBtn_st {
    logical_value, 0, "PushButtonStatus_Neutral" ;
    logical_value, 1, "PushButtonStatus_Pushed" ;
    logical_value, 2, "PushButtonStatus_Error" ;
    logical_value, 3, "PushButtonStatus_NotAvailable" ;
  }
  LIN_AirFlowSelectionFrontBtn_s {
    logical_value, 0, "PushButtonStatus_Neutral" ;
    logical_value, 1, "PushButtonStatus_Pushed" ;
    logical_value, 2, "PushButtonStatus_Error" ;
    logical_value, 3, "PushButtonStatus_NotAvailable" ;
  }
  LIN_AirFlowSelectionUpBtn_stat {
    logical_value, 0, "PushButtonStatus_Neutral" ;
    logical_value, 1, "PushButtonStatus_Pushed" ;
    logical_value, 2, "PushButtonStatus_Error" ;
    logical_value, 3, "PushButtonStatus_NotAvailable" ;
  }
  LIN_AirHeater_Stat {
    logical_value, 0, "Heater_Stat_Off" ;
    logical_value, 1, "Heater_Stat_Starting" ;
    logical_value, 2, "Heater_Stat_Running" ;
    logical_value, 3, "Heater_Stat_Standby" ;
    logical_value, 4, "Heater_Stat_AfterRun" ;
    logical_value, 5, "Heater_Stat_ErrorInterlock" ;
    logical_value, 6, "Heater_Stat_HeaterInterlock" ;
    logical_value, 7, "Heater_Stat_ADRInterlock" ;
    logical_value, 8, "Heater_Stat_CO2Running" ;
    logical_value, 9, "Heater_Stat_Spare2" ;
    logical_value, 10, "Heater_Stat_Spare3" ;
    logical_value, 11, "Heater_Stat_Spare4" ;
    logical_value, 12, "Heater_Stat_Spare5" ;
    logical_value, 13, "Heater_Stat_Spare6" ;
    logical_value, 14, "Heater_Stat_Error" ;
    logical_value, 15, "Heater_Stat_NotAvailable" ;
  }
  LIN_AirHeaterPowerStatus {
    physical_value, 0, 127, 1, 0, "Percent" ;
  }
  LIN_AirVent_IndicationCmd {
    logical_value, 0, "IndicationCmd_OFFLEDNotActivated" ;
    logical_value, 1, "IndicationCmd_ONLEDActivated" ;
  }
  LIN_AirWindscreen_IndicationCm {
    logical_value, 0, "IndicationCmd_OFFLEDNotActivated" ;
    logical_value, 1, "IndicationCmd_ONLEDActivated" ;
  }
  LIN_Area_9level_Indication_cmd {
    logical_value, 0, "Area_9Level_UP3_FRONT0_DOWN0" ;
    logical_value, 1, "Area_9Level_UP0_FRONT3_DOWN0" ;
    logical_value, 2, "Area_9Level_UP0_FRONT0_DOWN3" ;
    logical_value, 3, "Area_9Level_UP1_FRONT2_DOWN0" ;
    logical_value, 4, "Area_9Level_UP1_FRONT0_DOWN2" ;
    logical_value, 5, "Area_9Level_UP2_FRONT1_DOWN0" ;
    logical_value, 6, "Area_9Level_UP2_FRONT0_DOWN1" ;
    logical_value, 7, "Area_9Level_UP0_FRONT2_DOWN1" ;
    logical_value, 8, "Area_9Level_UP0_FRONT1_DOWN2" ;
    logical_value, 9, "Area_9Level_UP1_FRONT1_DOWN1" ;
    logical_value, 10, "Area_9Level_AllClosed" ;
    logical_value, 11, "Area_9Level_NoAirDistibutionSegmentDisplayed" ;
    logical_value, 12, "Area_9Level_Spare_2" ;
    logical_value, 13, "Area_9Level_Spare_3" ;
    logical_value, 14, "Area_9Level_Error" ;
    logical_value, 15, "Area_9Level_NotAvailable" ;
  }
  LIN_Auto_ButtonStatus {
    logical_value, 0, "PushButtonStatus_Neutral" ;
    logical_value, 1, "PushButtonStatus_Pushed" ;
    logical_value, 2, "PushButtonStatus_Error" ;
    logical_value, 3, "PushButtonStatus_NotAvailable" ;
  }
  LIN_AutoMode_IndicationCmd {
    logical_value, 0, "IndicationCmd_OFFLEDNotActivated" ;
    logical_value, 1, "IndicationCmd_ONLEDActivated" ;
  }
  LIN_CabInteriorTempVentilatedS {
    physical_value, 0, 1023, 0.125, -40, "DegreeC" ;
  } // 1022 Error; 1023 Not Available
  LIN_CFPM_stat {
    logical_value, 0, "OffOn_Off" ;
    logical_value, 1, "OffOn_On" ;
    logical_value, 2, "OffOn_Error" ;
    logical_value, 3, "OffOn_NotAvailable" ;
  }
  LIN_CFPMinputCurrent_stat {
    physical_value, 0, 255, 0.1, 0, "A" ;
  }
  LIN_CFPMinputVoltage_stat {
    physical_value, 0, 511, 0.1, 0, "V" ;
  }
  LIN_ClimateCtrlPanelSleep_cmd {
    logical_value, 0, "ClimateCtrlPanelSleep_cmd_NormalOperationMode" ;
    logical_value, 1, "ClimateCtrlPanelSleep_cmd_SleepMode" ;
    logical_value, 2, "ClimateCtrlPanelSleep_cmd_ReducedMode" ;
    logical_value, 3, "ClimateCtrlPanelSleep_cmd_WakeUpMode" ;
    logical_value, 6, "ClimateCtrlPanelSleep_cmd_Error" ;
    logical_value, 7, "ClimateCtrlPanelSleep_cmd_NotAvailable" ;
  }
  LIN_CTS_Solarradiance {
    physical_value, 0, 31, 50, 0, "W_per_m_squared" ;
  }
  LIN_CTS_Status {
    logical_value, 0, "CTS_Status_SensorOk" ;
    logical_value, 1, "CTS_Status_SensorDefect" ;
    logical_value, 2, "CTS_Status_SensorTestInitiated" ;
    logical_value, 3, "CTS_Status_NA" ;
  }
  LIN_CTS_Temperature {
    physical_value, 0, 4095, 0.1, -80, "DegreeC" ;
  }
  LIN_CTS_TempOutofRange {
    logical_value, 0, "CTS_TempOutofRange_TemperatureValueInRange" ;
    logical_value, 1, "CTS_TempOutofRange_TemperatureValueOutOfLowRange" ;
    logical_value, 2, "CTS_TempOutofRange_TemperatureValueOutOfHighRange" ;
    logical_value, 3, "CTS_TempOutofRange_NA" ;
  }
  LIN_Eco_ButtonStatus {
    logical_value, 0, "PushButtonStatus_Neutral" ;
    logical_value, 1, "PushButtonStatus_Pushed" ;
    logical_value, 2, "PushButtonStatus_Error" ;
    logical_value, 3, "PushButtonStatus_NotAvailable" ;
  }
  LIN_ECOmode_IndicationCmd {
    logical_value, 0, "IndicationCmd_OFFLEDNotActivated" ;
    logical_value, 1, "IndicationCmd_ONLEDActivated" ;
  }
  LIN_ElCondFanOutput_stat {
    physical_value, 0, 127, 1, 0, "Percent" ;
  }
  LIN_ElCondFanOutputCurrent_sta {
    physical_value, 0, 255, 0.1, 0, "A" ;
  }
  LIN_ElCondFanOutputVolt_stat {
    physical_value, 0, 511, 0.1, 0, "V" ;
  }
  LIN_ElecAcCompInputCurrent_sta {
    physical_value, 0, 255, 0.5, 0, "A" ;
  }
  LIN_ElecAcCompInVoltage_stat {
    physical_value, 0, 255, 0.5, 0, "V" ;
  }
  LIN_ElecAcCompOperation_stat {
    logical_value, 0, "ElecAcCompOperation_stat_CompressorOFF" ;
    logical_value, 1, "ElecAcCompOperation_stat_CompressorON" ;
    logical_value, 2, "ElecAcCompOperation_stat_PowerLimitation" ;
    logical_value, 3, "ElecAcCompOperation_stat_FailureOfElecACCompOrNotAvailable" ;
  }
  LIN_ElecAcCompSleepMode_stat {
    physical_value, 0, 255, 1, 0, "NotApplicable" ;
  }
  LIN_ElecAcCompSpeed_stat {
    physical_value, 0, 255, 50, 0, "rpm" ;
  }
  LIN_ElecAcCompTemp_stat {
    physical_value, 0, 255, 1, -50, "DegreeC" ;
  }
  LIN_ElecAcCompWaitMode_stat {
    physical_value, 0, 255, 1, 0, "NotApplicable" ;
  }
  LIN_FanCurrentCFanLStat {
    physical_value, 0, 255, 0.1, 0, "A" ;
  }
  LIN_FanCurrentCFanRStat {
    physical_value, 0, 255, 0.1, 0, "A" ;
  }
  LIN_FanSpeedCFanLStat {
    physical_value, 0, 8191, 1, 0, "rpm" ;
  }
  LIN_FanSpeedCFanRStat {
    physical_value, 0, 8191, 1, 0, "rpm" ;
  }
  LIN_FanVoltageCFanLStat {
    physical_value, 0, 511, 0.1, 0, "V" ;
  }
  LIN_FanVoltageCFanRStat {
    physical_value, 0, 511, 0.1, 0, "V" ;
  }
  LIN_FogSensor_CabAirRH {
    physical_value, 0, 511, 0.25, 0, "Percent" ;
  } // 510 Error ; 511 Not available
  LIN_FogSensor_CabAirTemp {
    physical_value, 0, 1023, 0.125, -40, "deg" ;
  } // 1022 Error ; 1023 Not available
  LIN_FogSensorWindscreenTemp_st {
    physical_value, 0, 2047, 0.0625, -40, "deg" ;
  } // 2046 Error ; 2047 Not available
  LIN_Memo_ButtonStatus {
    logical_value, 0, "PushButtonStatus_Neutral" ;
    logical_value, 1, "PushButtonStatus_Pushed" ;
    logical_value, 2, "PushButtonStatus_Error" ;
    logical_value, 3, "PushButtonStatus_NotAvailable" ;
  }
  LIN_Memo_IndicationCmd {
    logical_value, 0, "IndicationCmd_OFFLEDNotActivated" ;
    logical_value, 1, "IndicationCmd_ONLEDActivated" ;
  }
  LIN_ParkHeaterCooler_ButtonSta {
    logical_value, 0, "PushButtonStatus_Neutral" ;
    logical_value, 1, "PushButtonStatus_Pushed" ;
    logical_value, 2, "PushButtonStatus_Error" ;
    logical_value, 3, "PushButtonStatus_NotAvailable" ;
  }
  LIN_ParkingClimate_IndCmd {
    logical_value, 0, "ParkingClimate_IndicationCmd_NoSystemActivated" ;
    logical_value, 1, "ParkingClimate_IndicationCmd_ParkingHeaterActivated" ;
    logical_value, 2, "ParkingClimate_IndicationCmd_ParkCoolWithCompActivFullMode" ;
    logical_value, 3, "ParkingClimate_IndicationCmd_ParkCoolWithoutCompActivReducedMode" ;
    logical_value, 4, "ParkingClimate_IndicationCmd_ShortStopHeaterActivated" ;
    logical_value, 5, "ParkingClimate_IndicationCmd_Spare_01" ;
    logical_value, 6, "ParkingClimate_IndicationCmd_Error" ;
    logical_value, 7, "ParkingClimate_IndicationCmd_NotAvailable" ;
  }
  LIN_Recirc_ButtonStatus {
    logical_value, 0, "PushButtonStatus_Neutral" ;
    logical_value, 1, "PushButtonStatus_Pushed" ;
    logical_value, 2, "PushButtonStatus_Error" ;
    logical_value, 3, "PushButtonStatus_NotAvailable" ;
  }
  LIN_Recirc_IndicationCmd {
    logical_value, 0, "IndicationCmd_OFFLEDNotActivated" ;
    logical_value, 1, "IndicationCmd_ONLEDActivated" ;
  }
  LIN_Temperature_FreeWheelStatu {
    logical_value, 0, "FreeWheel_Status_NoMovement" ;
    logical_value, 1, "FreeWheel_Status_1StepClockwise" ;
    logical_value, 2, "FreeWheel_Status_2StepsClockwise" ;
    logical_value, 3, "FreeWheel_Status_3StepsClockwise" ;
    logical_value, 4, "FreeWheel_Status_4StepsClockwise" ;
    logical_value, 5, "FreeWheel_Status_5StepsClockwise" ;
    logical_value, 6, "FreeWheel_Status_6StepsClockwise" ;
    logical_value, 7, "FreeWheel_Status_1StepCounterClockwise" ;
    logical_value, 8, "FreeWheel_Status_2StepsCounterClockwise" ;
    logical_value, 9, "FreeWheel_Status_3StepsCounterClockwise" ;
    logical_value, 10, "FreeWheel_Status_4StepsCounterClockwise" ;
    logical_value, 11, "FreeWheel_Status_5StepsCounterClockwise" ;
    logical_value, 12, "FreeWheel_Status_6StepsCounterClockwise" ;
    logical_value, 13, "FreeWheel_Status_Spare" ;
    logical_value, 14, "FreeWheel_Status_Error" ;
    logical_value, 15, "FreeWheel_Status_NotAvailable" ;
  }
  LIN_TemperatureDec_ButtonStatu {
    logical_value, 0, "PushButtonStatus_Neutral" ;
    logical_value, 1, "PushButtonStatus_Pushed" ;
    logical_value, 2, "PushButtonStatus_Error" ;
    logical_value, 3, "PushButtonStatus_NotAvailable" ;
  }
  LIN_TemperatureInc_ButtonStatu {
    logical_value, 0, "PushButtonStatus_Neutral" ;
    logical_value, 1, "PushButtonStatus_Pushed" ;
    logical_value, 2, "PushButtonStatus_Error" ;
    logical_value, 3, "PushButtonStatus_NotAvailable" ;
  }
  LIN_TemperatureRqstIndicatio_c {
    logical_value, 0, "TemperatureRqstIndication_cmd_NoTempDisplayed" ;
    logical_value, 1, "TemperatureRqstIndication_cmd_Min" ;
    logical_value, 2, "TemperatureRqstIndication_cmd_15C" ;
    logical_value, 3, "TemperatureRqstIndication_cmd_16C" ;
    logical_value, 4, "TemperatureRqstIndication_cmd_16_5C" ;
    logical_value, 5, "TemperatureRqstIndication_cmd_17C" ;
    logical_value, 6, "TemperatureRqstIndication_cmd_17_5C" ;
    logical_value, 7, "TemperatureRqstIndication_cmd_18C" ;
    logical_value, 8, "TemperatureRqstIndication_cmd_18_5C" ;
    logical_value, 9, "TemperatureRqstIndication_cmd_19C" ;
    logical_value, 10, "TemperatureRqstIndication_cmd_19_5C" ;
    logical_value, 11, "TemperatureRqstIndication_cmd_20C" ;
    logical_value, 12, "TemperatureRqstIndication_cmd_20_5C" ;
    logical_value, 13, "TemperatureRqstIndication_cmd_21C" ;
    logical_value, 14, "TemperatureRqstIndication_cmd_21_5C" ;
    logical_value, 15, "TemperatureRqstIndication_cmd_22C" ;
    logical_value, 16, "TemperatureRqstIndication_cmd_22_5C" ;
    logical_value, 17, "TemperatureRqstIndication_cmd_23C" ;
    logical_value, 18, "TemperatureRqstIndication_cmd_23_5C" ;
    logical_value, 19, "TemperatureRqstIndication_cmd_24C" ;
    logical_value, 20, "TemperatureRqstIndication_cmd_24_5C" ;
    logical_value, 21, "TemperatureRqstIndication_cmd_25C" ;
    logical_value, 22, "TemperatureRqstIndication_cmd_25_5C" ;
    logical_value, 23, "TemperatureRqstIndication_cmd_26C" ;
    logical_value, 24, "TemperatureRqstIndication_cmd_27C" ;
    logical_value, 25, "TemperatureRqstIndication_cmd_28C" ;
    logical_value, 26, "TemperatureRqstIndication_cmd_29C" ;
    logical_value, 27, "TemperatureRqstIndication_cmd_Max" ;
    logical_value, 28, "TemperatureRqstIndication_cmd_Spare" ;
    logical_value, 29, "TemperatureRqstIndication_cmd_Spare_01" ;
    logical_value, 30, "TemperatureRqstIndication_cmd_Error" ;
    logical_value, 31, "TemperatureRqstIndication_cmd_NotAvailable" ;
  }
  LIN_WaterHeater_Stat {
    logical_value, 0, "Heater_Stat_Off" ;
    logical_value, 1, "Heater_Stat_Starting" ;
    logical_value, 2, "Heater_Stat_Running" ;
    logical_value, 3, "Heater_Stat_Standby" ;
    logical_value, 4, "Heater_Stat_AfterRun" ;
    logical_value, 5, "Heater_Stat_ErrorInterlock" ;
    logical_value, 6, "Heater_Stat_HeaterInterlock" ;
    logical_value, 7, "Heater_Stat_ADRInterlock" ;
    logical_value, 8, "Heater_Stat_CO2Running" ;
    logical_value, 9, "Heater_Stat_Spare2" ;
    logical_value, 10, "Heater_Stat_Spare3" ;
    logical_value, 11, "Heater_Stat_Spare4" ;
    logical_value, 12, "Heater_Stat_Spare5" ;
    logical_value, 13, "Heater_Stat_Spare6" ;
    logical_value, 14, "Heater_Stat_Error" ;
    logical_value, 15, "Heater_Stat_NotAvailable" ;
  }
  LIN_WaterHeaterPowerStatus {
    physical_value, 0, 255, 0.4, 0, "Percent" ;
  }
  LIN_WaterHeaterTemperature_Sta {
    physical_value, 0, 2047, 0.1, -40, "DegreeC" ;
  } // 2046 Error ; 2047 Not available
  LIN_WaterPumpStatus {
    logical_value, 0, "OffOn_Off" ;
    logical_value, 1, "OffOn_On" ;
    logical_value, 2, "OffOn_Error" ;
    logical_value, 3, "OffOn_NotAvailable" ;
  }
  LIN_WHMaint_stat_BurnerLfTm {
    physical_value, 0, 255, 20, 0, "h" ;
  } // 254 Error ; 255 Not Available
  LIN_WHMaint_stat_FanLfTime {
    physical_value, 0, 255, 20, 0, "h" ;
  } // 254 Error ; 255 Not Available
  LIN_WHMaint_stat_FuelPmpLfTm {
    physical_value, 0, 255, 20, 0, "h" ;
  } // 254 Error ; 255 Not Available
  LIN_WHMaint_stat_GlowPlgLfTm {
    physical_value, 0, 255, 20, 0, "h" ;
  } // 254 Error ; 255 Not Available
  LIN_WHMaint_stat_WtrPmpLfTm {
    physical_value, 0, 255, 20, 0, "h" ;
  } // 254 Error ; 255 Not Available
  LIN_WHRunTest_Stat1_BurnerTest {
    logical_value, 0, "BurnerTest_Status_BurnerTestSequenceValidated" ;
    logical_value, 1, "BurnerTest_Status_BurnerTestSequenceNotValidated" ;
    logical_value, 2, "BurnerTest_Status_Error" ;
    logical_value, 3, "BurnerTest_Status_NotAvailable" ;
  }
  LIN_WHRunTest_Stat1_CO2Level {
    physical_value, 0, 255, 0.08, -10, "Percent" ;
  } // 254 Error ; 255 Not Available
  LIN_WHRunTest_Stat1_FuelFeeding {
    logical_value, 0, "FuelFeeding_Status_FuelLineFeedingSequenceValidated" ;
    logical_value, 1, "FuelFeeding_Status_FuelLineFeedingSequenceNotValidated" ;
    logical_value, 2, "FuelFeeding_Status_Error" ;
    logical_value, 3, "FuelFeeding_Status_NotAvailable" ;
  }
  LIN_WHRunTest_Stat1_OpVoltage {
    physical_value, 0, 255, 0.14, 0, "V" ;
  } // 254 Error ; 255 Not Available
  LIN_WHRunTest_Stat1_SetPointTmp {
    logical_value, 0, "SetPointTemp_14_0DegC" ;
    logical_value, 1, "SetPointTemp_15_0DegC" ;
    logical_value, 2, "SetPointTemp_16_0DegC" ;
    logical_value, 3, "SetPointTemp_16_5DegC" ;
    logical_value, 4, "SetPointTemp_17_0DegC" ;
    logical_value, 5, "SetPointTemp_17_5DegC" ;
    logical_value, 6, "SetPointTemp_18_0DegC" ;
    logical_value, 7, "SetPointTemp_18_5DegC" ;
    logical_value, 8, "SetPointTemp_19_0DegC" ;
    logical_value, 9, "SetPointTemp_19_5DegC" ;
    logical_value, 10, "SetPointTemp_20_0DegC" ;
    logical_value, 11, "SetPointTemp_20_5DegC" ;
    logical_value, 12, "SetPointTemp_21_0DegC" ;
    logical_value, 13, "SetPointTemp_21_5DegC" ;
    logical_value, 14, "SetPointTemp_22_0DegC" ;
    logical_value, 15, "SetPointTemp_22_5DegC" ;
    logical_value, 16, "SetPointTemp_23_0DegC" ;
    logical_value, 17, "SetPointTemp_23_5DegC" ;
    logical_value, 18, "SetPointTemp_24_0DegC" ;
    logical_value, 19, "SetPointTemp_24_5DegC" ;
    logical_value, 20, "SetPointTemp_25_0DegC" ;
    logical_value, 21, "SetPointTemp_25_5DegC" ;
    logical_value, 22, "SetPointTemp_26_0DegC" ;
    logical_value, 23, "SetPointTemp_27_0DegC" ;
    logical_value, 24, "SetPointTemp_28_0DegC" ;
    logical_value, 25, "SetPointTemp_29_0DegC" ;
    logical_value, 26, "SetPointTemp_30_0DegC" ;
    logical_value, 27, "SetPointTemp_Spare" ;
    logical_value, 28, "SetPointTemp_Spare_01" ;
    logical_value, 29, "SetPointTemp_Spare_02" ;
    logical_value, 30, "SetPointTemp_Error" ;
    logical_value, 31, "SetPointTemp_NotAvailable" ;
  }
  LIN_WHRunTest_Stat1_TempOutlet {
    physical_value, 0, 255, 1, -50, "DegreeC" ;
  } // 254 Error ; 255 Not Available
  LIN_WHRunTest_Stat1_WaterSetTmp {
    physical_value, 0, 127, 1, 0, "DegreeC" ;
  } // 126 Error ; 127 Not available
  LIN_WHRunTest_Stat2_CabTemp {
    physical_value, 0, 8191, 0.025, -40, "DegreeC" ;
  } // 8190 Error; 8191 Not Available
  LIN_WHRunTest_Stat2_TempInlet {
    physical_value, 0, 1023, 0.125, -50, "DegreeC" ;
  } // 1022 Error ; 1023 Not available
  LIN_WHRunTest_Stat2_WaterTemp {
    physical_value, 0, 2047, 0.1, -40, "DegreeC" ;
  } // 2046 Error ; 2047 Not available
  LIN_WindscreenDefrost_ButtonSt {
    logical_value, 0, "PushButtonStatus_Neutral" ;
    logical_value, 1, "PushButtonStatus_Pushed" ;
    logical_value, 2, "PushButtonStatus_Error" ;
    logical_value, 3, "PushButtonStatus_NotAvailable" ;
  }
  LIN_WindscreenDefrostInd_cmd {
    logical_value, 0, "IndicationCmd_OFFLEDNotActivated" ;
    logical_value, 1, "IndicationCmd_ONLEDActivated" ;
  }
  PH_Activation_cmd {
    logical_value, 0, "PH_Activation_cmd_ParkingHeaterOFF" ;
    logical_value, 1, "PH_Activation_cmd_ParkingHeaterOFFShortStop" ;
    logical_value, 2, "PH_Activation_cmd_ParkingHeaterON" ;
    logical_value, 3, "PH_Activation_cmd_ParkingHeaterONForced" ;
    logical_value, 4, "PH_Activation_cmd_PumpOnly" ;
    logical_value, 5, "PH_Activation_cmd_HeaterWithoutPump" ;
    logical_value, 6, "PH_Activation_cmd_Error" ;
    logical_value, 7, "PH_Activation_cmd_NotAvailable" ;
  }
  PHMasterMode_cmd_DosingPump {
    physical_value, 0, 127, 1, 0, "Percent" ;
  } // 126 Error ; 127 Not available
  PHMasterMode_cmd_GlowPlug {
    physical_value, 0, 127, 1, 0, "Percent" ;
  } // 126 Error ; 127 Not available
  PHMasterMode_cmd_HeatingFan {
    physical_value, 0, 127, 1, 0, "Percent" ;
  } // 126 Error ; 127 Not available
  PHMasterMode_cmd_RunningTime {
    physical_value, 0, 255, 1, 0, "s" ;
  }
  PHMasterMode_cmd_WaterPump {
    logical_value, 0, "OffOn_Off" ;
    logical_value, 1, "OffOn_On" ;
    logical_value, 2, "OffOn_Error" ;
    logical_value, 3, "OffOn_NotAvailable" ;
  }
  PHRunTest_cmd_Burner_cmd {
    logical_value, 0, "Burner_cmd_BurnerSequenceStarted" ;
    logical_value, 1, "Burner_cmd_BurnerSequenceStopped" ;
    logical_value, 2, "Burner_cmd_Error" ;
    logical_value, 3, "Burner_cmd_NotAvailable" ;
  }
  PHRunTest_cmd_CO2Adjustment_cmd {
    logical_value, 0, "CO2Adjustment_cmd_CO2AdjustmentSequenceStarted" ;
    logical_value, 1, "CO2Adjustment_cmd_CO2AdjustmentSequenceStopped" ;
    logical_value, 2, "CO2Adjustment_cmd_Error" ;
    logical_value, 3, "CO2Adjustment_cmd_NotAvailable" ;
  }
  PHRunTest_cmd_CO2Level {
    physical_value, 0, 255, 0.08, -10, "Percent" ;
  } // 254 Error ; 255 Not Available
  PHRunTest_cmd_FuelFeeding_cmd {
    logical_value, 0, "FuelFeeding_cmd_FuelLineFeedingSequenceStarted" ;
    logical_value, 1, "FuelFeeding_cmd_FuelLineFeedingSequenceStopped" ;
    logical_value, 2, "FuelFeeding_cmd_Error" ;
    logical_value, 3, "FuelFeeding_cmd_NotAvailable" ;
  }
  PHRunTest_cmd_FuelFeedTime {
    physical_value, 0, 511, 1, 0, "s" ;
  } // 510 Error ; 511 Not Available
  PHRunTest_cmd_ReadSensor {
    logical_value, 0, "PHReadSensor_NoRequest" ;
    logical_value, 1, "PHReadSensor_OperatingVoltage" ;
    logical_value, 2, "PHReadSensor_CabTempOnlyAH" ;
    logical_value, 3, "PHReadSensor_SetTempOnlyAH" ;
    logical_value, 4, "PHReadSensor_TempAirOutletOnlyAH" ;
    logical_value, 5, "PHReadSensor_TempAirInletOnlyAH" ;
    logical_value, 6, "PHReadSensor_WaterTempStatusOnlyWH" ;
    logical_value, 7, "PHReadSensor_WaterSetTempOnlyWH" ;
    logical_value, 8, "PHReadSensor_AllComponents" ;
    logical_value, 14, "PHReadSensor_Error" ;
    logical_value, 15, "PHReadSensor_NotAvailable" ;
  }
  PHRunTest_cmd_ResetCounter {
    logical_value, 0, "PHResetCounter_NoReset" ;
    logical_value, 1, "PHResetCounter_ResetCounterOfFuelPumpRestLifeTime" ;
    logical_value, 2, "PHResetCounter_ResetCounterOfBurnerRestLifeTime" ;
    logical_value, 3, "PHResetCounter_ResetCounterOfGlowPlugRestLifeTime" ;
    logical_value, 4, "PHResetCounter_ResetCounterOfHeatingFanRestLifeTime" ;
    logical_value, 5, "PHResetCounter_ResetCounterOfWaterPumpRestLifeTime" ;
    logical_value, 6, "PHResetCounter_ResetAllCounters" ;
    logical_value, 14, "PHResetCounter_Error" ;
    logical_value, 15, "PHResetCounter_NotAvailable" ;
  }
  PHRunTest_cmd_RstFaultCodes {
    logical_value, 0, "PHRstFaultCodes_NoReset" ;
    logical_value, 1, "PHRstFaultCodes_ResetOfFaultCodesValidated" ;
    logical_value, 2, "PHRstFaultCodes_Error" ;
    logical_value, 3, "PHRstFaultCodes_NotAvailable" ;
  }
  ResponseError_T {
    logical_value, 0, "No Error" ;
    logical_value, 1, "Error" ;
  }
  TempRqst_cmd {
    logical_value, 0, "TempRqst_cmd_14C" ;
    logical_value, 1, "TempRqst_cmd_15C" ;
    logical_value, 2, "TempRqst_cmd_16C" ;
    logical_value, 3, "TempRqst_cmd_16_5C" ;
    logical_value, 4, "TempRqst_cmd_17C" ;
    logical_value, 5, "TempRqst_cmd_17_5C" ;
    logical_value, 6, "TempRqst_cmd_18C" ;
    logical_value, 7, "TempRqst_cmd_18_5C" ;
    logical_value, 8, "TempRqst_cmd_19C" ;
    logical_value, 9, "TempRqst_cmd_19_5C" ;
    logical_value, 10, "TempRqst_cmd_20C" ;
    logical_value, 11, "TempRqst_cmd_20_5C" ;
    logical_value, 12, "TempRqst_cmd_21C" ;
    logical_value, 13, "TempRqst_cmd_21_5C" ;
    logical_value, 14, "TempRqst_cmd_22C" ;
    logical_value, 15, "TempRqst_cmd_22_5C" ;
    logical_value, 16, "TempRqst_cmd_23C" ;
    logical_value, 17, "TempRqst_cmd_23_5C" ;
    logical_value, 18, "TempRqst_cmd_24C" ;
    logical_value, 19, "TempRqst_cmd_24_5C" ;
    logical_value, 20, "TempRqst_cmd_25C" ;
    logical_value, 21, "TempRqst_cmd_25_5C" ;
    logical_value, 22, "TempRqst_cmd_26C" ;
    logical_value, 23, "TempRqst_cmd_27C" ;
    logical_value, 24, "TempRqst_cmd_28C" ;
    logical_value, 25, "TempRqst_cmd_29C" ;
    logical_value, 26, "TempRqst_cmd_30C" ;
    logical_value, 27, "TempRqst_cmd_Spare" ;
    logical_value, 28, "TempRqst_cmd_Spare_01" ;
    logical_value, 29, "TempRqst_cmd_Spare_02" ;
    logical_value, 30, "TempRqst_cmd_Error" ;
    logical_value, 31, "TempRqst_cmd_NotAvailable" ;
  }
  WaterHeaterSetTemp_cmd {
    physical_value, 0, 127, 1, 0, "DegreeC" ;
  }
}

Signal_representation {
  AtmospherePressureStatus: AtmospherePressureStatus ;
  BacklightCmd: BacklightCmd ;
  CabTemperature_Status: CabTemperature_Status ;
  CTS_Downtime: CTS_Downtime ;
  CTS_DrvWindowStat: CTS_DrvWindowStat ;
  CTS_GlazingType: CTS_GlazingType ;
  CTS_IradianceDrvSide: CTS_IradianceDrvSide ;
  CTS_IradiancePassSide: CTS_IradiancePassSide ;
  CTS_PassWindowStat: CTS_PassWindowStat ;
  CTS_RearDrvWindowStat: CTS_RearDrvWindowStat ;
  CTS_RearPassWindowStat: CTS_RearPassWindowStat ;
  CTS_SunBlindStat: CTS_SunBlindStat ;
  CTS_SunroofStat: CTS_SunroofStat ;
  DiagInfoCabHeater: DiagInfoCabHeater ;
  DiagInfoCCP: DiagInfoCCP ;
  DiagInfoCFanL: DiagInfoCFanL ;
  DiagInfoCFanR: DiagInfoCFanR ;
  DiagInfoCFPM: DiagInfoCFPM ;
  DiagInfoDEFS: DiagInfoDEFS ;
  DiagInfoEACC: DiagInfoEACC ;
  DiagInfoWaterHeater: DiagInfoWaterHeater ;
  ElecAcCompDrive_cmd: ElecAcCompDrive_cmd ;
  ElecAcCompTargetSpeed_cmd: ElecAcCompTargetSpeed_cmd ;
  ElecCondenserFanActivation_cmd: ElecCondenserFanActivation_cmd ;
  ElecCondFanOutputTarget_cmd: ElecCondFanOutputTarget_cmd ;
  FanDirectionCFanLCmd: FanDirectionCFanLCmd ;
  FanDirectionCFanRCmd: FanDirectionCFanRCmd ;
  FanSpeedCFanLCmd: FanSpeedCFanLCmd ;
  FanSpeedCFanRCmd: FanSpeedCFanRCmd ;
  FuncIndIlluminationLevel: FuncIndIlluminationLevel ;
  LIN_AC_ButtonStatus: LIN_AC_ButtonStatus ;
  LIN_AC_HVACFanIndication_cmd: LIN_AC_HVACFanIndication_cmd ;
  LIN_ACmode_IndicationCmd: LIN_ACmode_IndicationCmd ;
  LIN_AHMaint_stat_BurnerLfTm: LIN_AHMaint_stat_BurnerLfTm ;
  LIN_AHMaint_stat_FanLfTime: LIN_AHMaint_stat_FanLfTime ;
  LIN_AHMaint_stat_FuelPmpLfTm: LIN_AHMaint_stat_FuelPmpLfTm ;
  LIN_AHMaint_stat_GlowPlgLfTm: LIN_AHMaint_stat_GlowPlgLfTm ;
  LIN_AHMaint_stat_WtrPmpLfTm: LIN_AHMaint_stat_WtrPmpLfTm ;
  LIN_AHRunTest_Stat1_BurnerTest: LIN_AHRunTest_Stat1_BurnerTest ;
  LIN_AHRunTest_Stat1_CO2Level: LIN_AHRunTest_Stat1_CO2Level ;
  LIN_AHRunTest_Stat1_FuelFeeding: LIN_AHRunTest_Stat1_FuelFeeding ;
  LIN_AHRunTest_Stat1_OpVoltage: LIN_AHRunTest_Stat1_OpVoltage ;
  LIN_AHRunTest_Stat1_SetPointTmp: LIN_AHRunTest_Stat1_SetPointTmp ;
  LIN_AHRunTest_Stat1_TempOutlet: LIN_AHRunTest_Stat1_TempOutlet ;
  LIN_AHRunTest_Stat1_WaterSetTmp: LIN_AHRunTest_Stat1_WaterSetTmp ;
  LIN_AHRunTest_Stat2_CabTemp: LIN_AHRunTest_Stat2_CabTemp ;
  LIN_AHRunTest_Stat2_TempInlet: LIN_AHRunTest_Stat2_TempInlet ;
  LIN_AHRunTest_Stat2_WaterTemp: LIN_AHRunTest_Stat2_WaterTemp ;
  LIN_AirBlowerSpeed_FreeWheelSt: LIN_AirBlowerSpeed_FreeWheelSt ;
  LIN_AirFloor_IndicationCmd: LIN_AirFloor_IndicationCmd ;
  LIN_AirFlowSelectionDownBtn_st: LIN_AirFlowSelectionDownBtn_st ;
  LIN_AirFlowSelectionFrontBtn_s: LIN_AirFlowSelectionFrontBtn_s ;
  LIN_AirFlowSelectionUpBtn_stat: LIN_AirFlowSelectionUpBtn_stat ;
  LIN_AirHeater_Stat: LIN_AirHeater_Stat ;
  LIN_AirHeaterPowerStatus: LIN_AirHeaterPowerStatus ;
  LIN_AirVent_IndicationCmd: LIN_AirVent_IndicationCmd ;
  LIN_AirWindscreen_IndicationCm: LIN_AirWindscreen_IndicationCm ;
  LIN_Area_9level_Indication_cmd: LIN_Area_9level_Indication_cmd ;
  LIN_Auto_ButtonStatus: LIN_Auto_ButtonStatus ;
  LIN_AutoMode_IndicationCmd: LIN_AutoMode_IndicationCmd ;
  LIN_CabInteriorTempVentilatedS: LIN_CabInteriorTempVentilatedS ;
  LIN_CFPM_stat: LIN_CFPM_stat ;
  LIN_CFPMinputCurrent_stat: LIN_CFPMinputCurrent_stat ;
  LIN_CFPMinputVoltage_stat: LIN_CFPMinputVoltage_stat ;
  LIN_ClimateCtrlPanelSleep_cmd: LIN_ClimateCtrlPanelSleep_cmd ;
  LIN_CTS_Solarradiance: LIN_CTS_Solarradiance ;
  LIN_CTS_Status: LIN_CTS_Status ;
  LIN_CTS_Temperature: LIN_CTS_Temperature ;
  LIN_CTS_TempOutofRange: LIN_CTS_TempOutofRange ;
  LIN_Eco_ButtonStatus: LIN_Eco_ButtonStatus ;
  LIN_ECOmode_IndicationCmd: LIN_ECOmode_IndicationCmd ;
  LIN_ElCondFanOutput_stat: LIN_ElCondFanOutput_stat ;
  LIN_ElCondFanOutputCurrent_sta: LIN_ElCondFanOutputCurrent_sta ;
  LIN_ElCondFanOutputVolt_stat: LIN_ElCondFanOutputVolt_stat ;
  LIN_ElecAcCompInputCurrent_sta: LIN_ElecAcCompInputCurrent_sta ;
  LIN_ElecAcCompInVoltage_stat: LIN_ElecAcCompInVoltage_stat ;
  LIN_ElecAcCompOperation_stat: LIN_ElecAcCompOperation_stat ;
  LIN_ElecAcCompSleepMode_stat: LIN_ElecAcCompSleepMode_stat ;
  LIN_ElecAcCompSpeed_stat: LIN_ElecAcCompSpeed_stat ;
  LIN_ElecAcCompTemp_stat: LIN_ElecAcCompTemp_stat ;
  LIN_ElecAcCompWaitMode_stat: LIN_ElecAcCompWaitMode_stat ;
  LIN_FanCurrentCFanLStat: LIN_FanCurrentCFanLStat ;
  LIN_FanCurrentCFanRStat: LIN_FanCurrentCFanRStat ;
  LIN_FanSpeedCFanLStat: LIN_FanSpeedCFanLStat ;
  LIN_FanSpeedCFanRStat: LIN_FanSpeedCFanRStat ;
  LIN_FanVoltageCFanLStat: LIN_FanVoltageCFanLStat ;
  LIN_FanVoltageCFanRStat: LIN_FanVoltageCFanRStat ;
  LIN_FogSensor_CabAirRH: LIN_FogSensor_CabAirRH ;
  LIN_FogSensor_CabAirTemp: LIN_FogSensor_CabAirTemp ;
  LIN_FogSensorWindscreenTemp_st: LIN_FogSensorWindscreenTemp_st ;
  LIN_Memo_ButtonStatus: LIN_Memo_ButtonStatus ;
  LIN_Memo_IndicationCmd: LIN_Memo_IndicationCmd ;
  LIN_ParkHeaterCooler_ButtonSta: LIN_ParkHeaterCooler_ButtonSta ;
  LIN_ParkingClimate_IndCmd: LIN_ParkingClimate_IndCmd ;
  LIN_Recirc_ButtonStatus: LIN_Recirc_ButtonStatus ;
  LIN_Recirc_IndicationCmd: LIN_Recirc_IndicationCmd ;
  LIN_Temperature_FreeWheelStatu: LIN_Temperature_FreeWheelStatu ;
  LIN_TemperatureDec_ButtonStatu: LIN_TemperatureDec_ButtonStatu ;
  LIN_TemperatureInc_ButtonStatu: LIN_TemperatureInc_ButtonStatu ;
  LIN_TemperatureRqstIndicatio_c: LIN_TemperatureRqstIndicatio_c ;
  LIN_WaterHeater_Stat: LIN_WaterHeater_Stat ;
  LIN_WaterHeaterPowerStatus: LIN_WaterHeaterPowerStatus ;
  LIN_WaterHeaterTemperature_Sta: LIN_WaterHeaterTemperature_Sta ;
  LIN_WaterPumpStatus: LIN_WaterPumpStatus ;
  LIN_WHMaint_stat_BurnerLfTm: LIN_WHMaint_stat_BurnerLfTm ;
  LIN_WHMaint_stat_FanLfTime: LIN_WHMaint_stat_FanLfTime ;
  LIN_WHMaint_stat_FuelPmpLfTm: LIN_WHMaint_stat_FuelPmpLfTm ;
  LIN_WHMaint_stat_GlowPlgLfTm: LIN_WHMaint_stat_GlowPlgLfTm ;
  LIN_WHMaint_stat_WtrPmpLfTm: LIN_WHMaint_stat_WtrPmpLfTm ;
  LIN_WHRunTest_Stat1_BurnerTest: LIN_WHRunTest_Stat1_BurnerTest ;
  LIN_WHRunTest_Stat1_CO2Level: LIN_WHRunTest_Stat1_CO2Level ;
  LIN_WHRunTest_Stat1_FuelFeeding: LIN_WHRunTest_Stat1_FuelFeeding ;
  LIN_WHRunTest_Stat1_OpVoltage: LIN_WHRunTest_Stat1_OpVoltage ;
  LIN_WHRunTest_Stat1_SetPointTmp: LIN_WHRunTest_Stat1_SetPointTmp ;
  LIN_WHRunTest_Stat1_TempOutlet: LIN_WHRunTest_Stat1_TempOutlet ;
  LIN_WHRunTest_Stat1_WaterSetTmp: LIN_WHRunTest_Stat1_WaterSetTmp ;
  LIN_WHRunTest_Stat2_CabTemp: LIN_WHRunTest_Stat2_CabTemp ;
  LIN_WHRunTest_Stat2_TempInlet: LIN_WHRunTest_Stat2_TempInlet ;
  LIN_WHRunTest_Stat2_WaterTemp: LIN_WHRunTest_Stat2_WaterTemp ;
  LIN_WindscreenDefrost_ButtonSt: LIN_WindscreenDefrost_ButtonSt ;
  LIN_WindscreenDefrostInd_cmd: LIN_WindscreenDefrostInd_cmd ;
  PH_Activation_cmd: PH_Activation_cmd ;
  PHMasterMode_cmd_DosingPump: PHMasterMode_cmd_DosingPump ;
  PHMasterMode_cmd_GlowPlug: PHMasterMode_cmd_GlowPlug ;
  PHMasterMode_cmd_HeatingFan: PHMasterMode_cmd_HeatingFan ;
  PHMasterMode_cmd_RunningTime: PHMasterMode_cmd_RunningTime ;
  PHMasterMode_cmd_WaterPump: PHMasterMode_cmd_WaterPump ;
  PHRunTest_cmd_Burner_cmd: PHRunTest_cmd_Burner_cmd ;
  PHRunTest_cmd_CO2Adjustment_cmd: PHRunTest_cmd_CO2Adjustment_cmd ;
  PHRunTest_cmd_CO2Level: PHRunTest_cmd_CO2Level ;
  PHRunTest_cmd_FuelFeeding_cmd: PHRunTest_cmd_FuelFeeding_cmd ;
  PHRunTest_cmd_FuelFeedTime: PHRunTest_cmd_FuelFeedTime ;
  PHRunTest_cmd_ReadSensor: PHRunTest_cmd_ReadSensor ;
  PHRunTest_cmd_ResetCounter: PHRunTest_cmd_ResetCounter ;
  PHRunTest_cmd_RstFaultCodes: PHRunTest_cmd_RstFaultCodes ;
  ResponseError_T: ResponseErrorCabHeater, ResponseErrorCCP, ResponseErrorCFAN_L, ResponseErrorCFAN_R, ResponseErrorCFPM, ResponseErrorDEFS, ResponseErrorEACC, ResponseErrorWaterHeater ;
  TempRqst_cmd: TempRqst_cmd ;
  WaterHeaterSetTemp_cmd: WaterHeaterSetTemp_cmd ;
}
